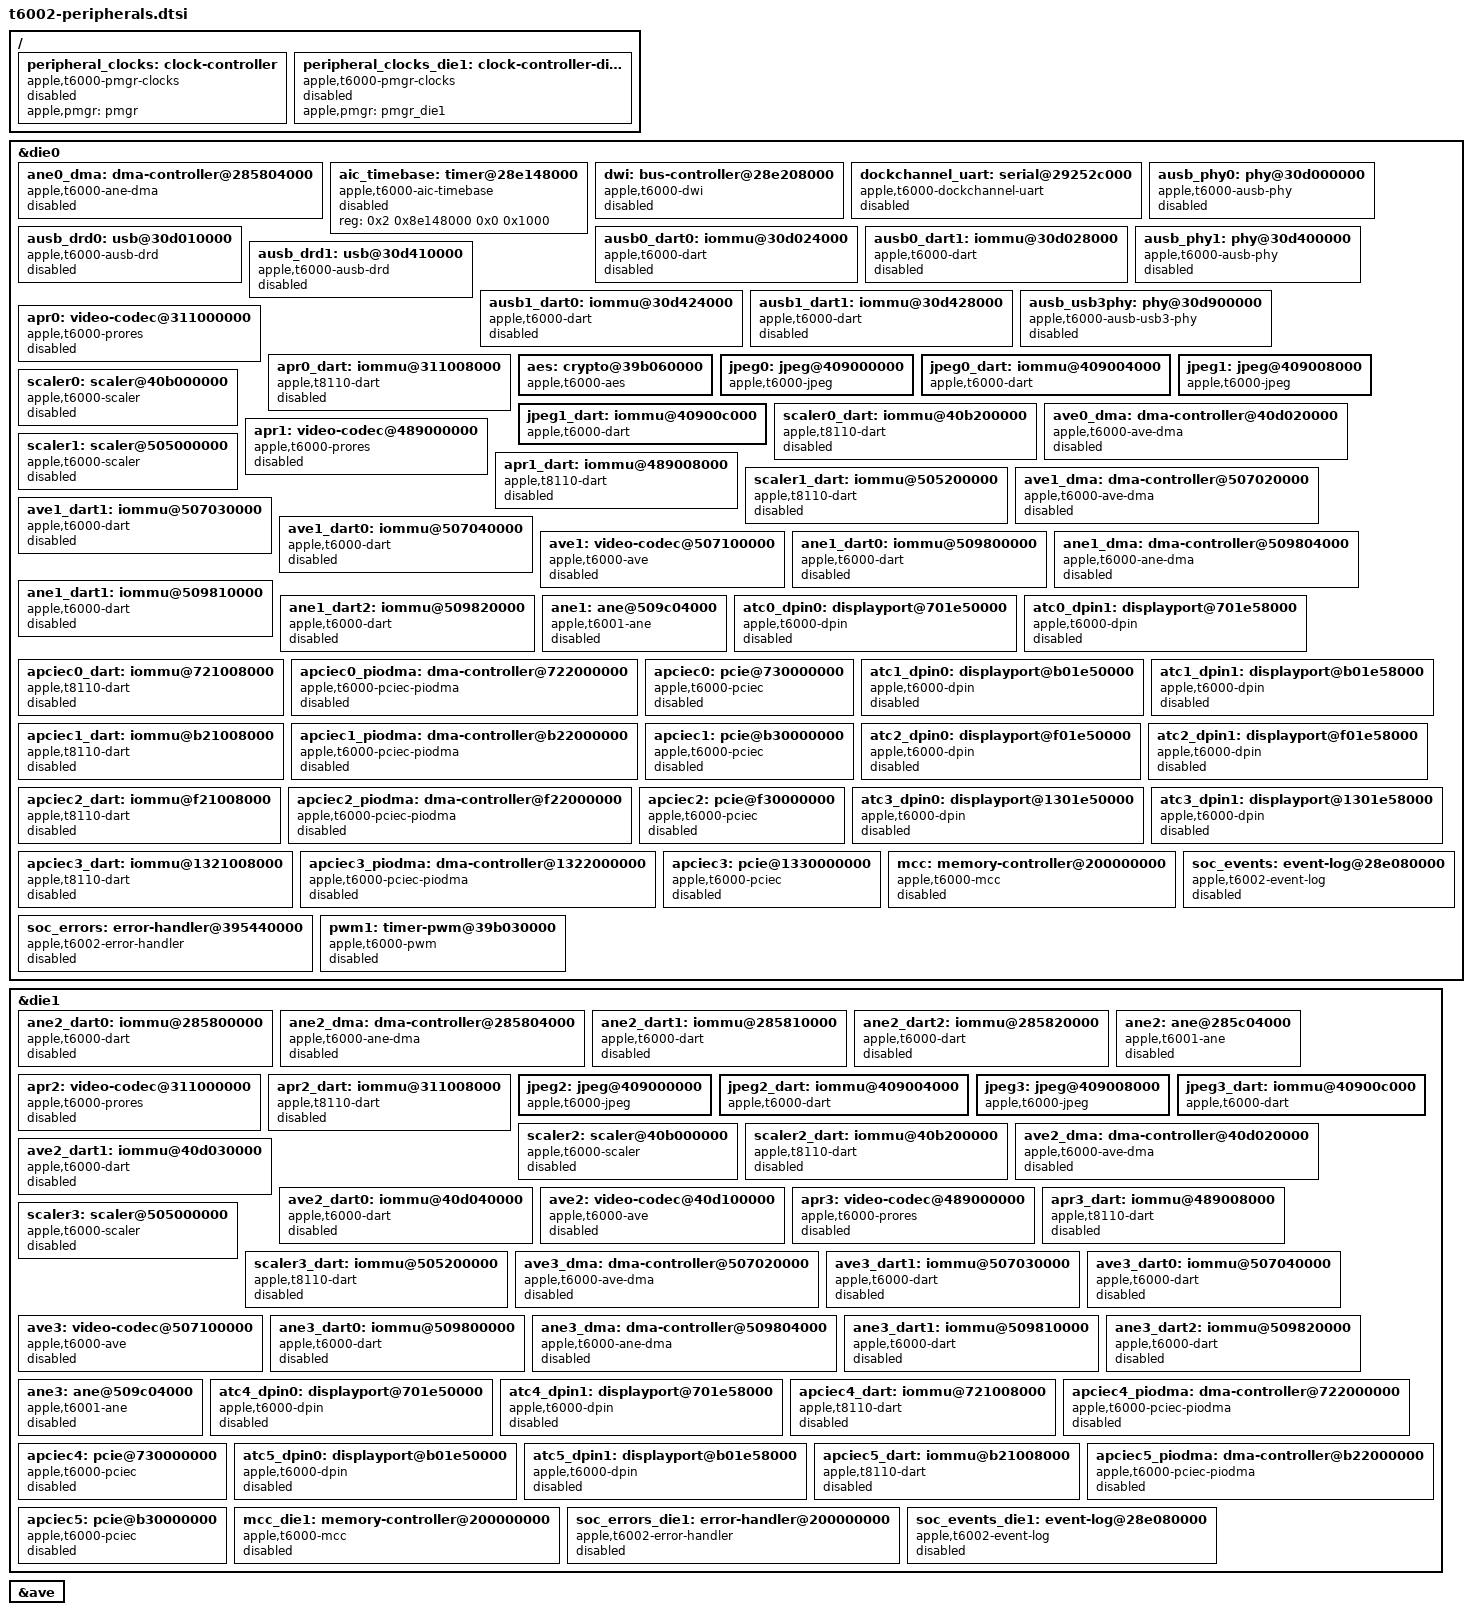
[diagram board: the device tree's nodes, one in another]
// SPDX-License-Identifier: GPL-2.0+ OR MIT
/* Disabled resource descriptions for T6002. */

&die0 {
	ane0_dma: dma-controller@285804000 {
		compatible = "apple,t6000-ane-dma", "apple,ane-dma";
		reg = <0x2 0x85804000 0x0 0x4000>;
		interrupt-parent = <&aic>;
		interrupts = <AIC_IRQ 0 771 IRQ_TYPE_LEVEL_HIGH>;
		power-domains = <&ps_ane_sys>;
		status = "disabled";
	};

	aic_timebase: timer@28e148000 {
		compatible = "apple,t6000-aic-timebase", "apple,aic-timebase";
		reg = <0x2 0x8e148000 0x0 0x1000>;
		status = "disabled";
	};

	dwi: bus-controller@28e208000 {
		compatible = "apple,t6000-dwi", "apple,dwi";
		reg = <0x2 0x8e208000 0x0 0x4000>;
		interrupt-parent = <&aic>;
		interrupts = <AIC_IRQ 0 22 IRQ_TYPE_LEVEL_HIGH>;
		power-domains = <&ps_dwi>;
		status = "disabled";
	};

	/* The DebugUSB DockChannel serial channel; RX is drained in software. */
	dockchannel_uart: serial@29252c000 {
		compatible = "apple,t6000-dockchannel-uart", "apple,dockchannel-uart";
		reg = <0x2 0x9252c000 0x0 0x4000>,
		      <0x2 0x92528000 0x0 0x4000>,
		      <0x2 0x9250c000 0x0 0x18>;
		reg-names = "data", "config", "irq";
		interrupt-parent = <&aic>;
		interrupts = <AIC_IRQ 0 620 IRQ_TYPE_LEVEL_HIGH>;
		apple,sw-drain;
		status = "disabled";
	};

	ausb_phy0: phy@30d000000 {
		compatible = "apple,t6000-ausb-phy", "apple,ausb-phy";
		reg = <0x3 0x0d000000 0x0 0x4000>;
		power-domains = <&ps_c0_usbctl>;
		#phy-cells = <0>;
		phys = <&ausb_usb3phy>;
		status = "disabled";
	};

	ausb_drd0: usb@30d010000 {
		compatible = "apple,t6000-ausb-drd", "apple,ausb-drd";
		reg = <0x3 0x0d010000 0x0 0x11800>,
		      <0x3 0x0d020000 0x0 0x4000>,
		      <0x3 0x0d01c100 0x0 0x4000>,
		      <0x3 0x0d000000 0x0 0x2c000>;
		interrupt-parent = <&aic>;
		interrupts = <AIC_IRQ 0 1155 IRQ_TYPE_LEVEL_HIGH>,
			     <AIC_IRQ 0 1156 IRQ_TYPE_LEVEL_HIGH>,
			     <AIC_IRQ 0 1157 IRQ_TYPE_LEVEL_HIGH>,
			     <AIC_IRQ 0 1158 IRQ_TYPE_LEVEL_HIGH>;
		power-domains = <&ps_c0_usb31drd>;
		iommus = <&ausb0_dart0 3>, <&ausb0_dart1 3>;
		phys = <&ausb_phy0>;
		status = "disabled";
	};

	ausb0_dart0: iommu@30d024000 {
		compatible = "apple,t6000-dart", "apple,t8110-dart";
		reg = <0x3 0x0d024000 0x0 0x4000>;
		interrupt-parent = <&aic>;
		interrupts = <AIC_IRQ 0 1154 IRQ_TYPE_LEVEL_HIGH>;
		#iommu-cells = <1>;
		status = "disabled";
	};

	ausb0_dart1: iommu@30d028000 {
		compatible = "apple,t6000-dart", "apple,t8110-dart";
		reg = <0x3 0x0d028000 0x0 0x4000>;
		interrupt-parent = <&aic>;
		interrupts = <AIC_IRQ 0 1154 IRQ_TYPE_LEVEL_HIGH>;
		#iommu-cells = <1>;
		status = "disabled";
	};

	ausb_phy1: phy@30d400000 {
		compatible = "apple,t6000-ausb-phy", "apple,ausb-phy";
		reg = <0x3 0x0d400000 0x0 0x4000>;
		power-domains = <&ps_c1_usbctl>;
		#phy-cells = <0>;
		phys = <&ausb_usb3phy>;
		status = "disabled";
	};

	ausb_drd1: usb@30d410000 {
		compatible = "apple,t6000-ausb-drd", "apple,ausb-drd";
		reg = <0x3 0x0d410000 0x0 0x11800>,
		      <0x3 0x0d420000 0x0 0x4000>,
		      <0x3 0x0d41c100 0x0 0x4000>,
		      <0x3 0x0d400000 0x0 0x2c000>;
		interrupt-parent = <&aic>;
		interrupts = <AIC_IRQ 0 1163 IRQ_TYPE_LEVEL_HIGH>,
			     <AIC_IRQ 0 1164 IRQ_TYPE_LEVEL_HIGH>,
			     <AIC_IRQ 0 1165 IRQ_TYPE_LEVEL_HIGH>,
			     <AIC_IRQ 0 1166 IRQ_TYPE_LEVEL_HIGH>;
		power-domains = <&ps_c1_usb31drd>;
		iommus = <&ausb1_dart0 3>, <&ausb1_dart1 3>;
		phys = <&ausb_phy1>;
		status = "disabled";
	};

	ausb1_dart0: iommu@30d424000 {
		compatible = "apple,t6000-dart", "apple,t8110-dart";
		reg = <0x3 0x0d424000 0x0 0x4000>;
		interrupt-parent = <&aic>;
		interrupts = <AIC_IRQ 0 1162 IRQ_TYPE_LEVEL_HIGH>;
		#iommu-cells = <1>;
		status = "disabled";
	};

	ausb1_dart1: iommu@30d428000 {
		compatible = "apple,t6000-dart", "apple,t8110-dart";
		reg = <0x3 0x0d428000 0x0 0x4000>;
		interrupt-parent = <&aic>;
		interrupts = <AIC_IRQ 0 1162 IRQ_TYPE_LEVEL_HIGH>;
		#iommu-cells = <1>;
		status = "disabled";
	};

	ausb_usb3phy: phy@30d900000 {
		compatible = "apple,t6000-ausb-usb3-phy", "apple,ausb-usb3-phy";
		reg = <0x3 0x0d900000 0x0 0x4000>,
		      <0x3 0x0d980000 0x0 0x4000>,
		      <0x3 0x0d982000 0x0 0x4000>,
		      <0x3 0x0d982200 0x0 0x4000>,
		      <0x3 0x0d982800 0x0 0x4000>,
		      <0x3 0x0d982a00 0x0 0x4000>,
		      <0x3 0x0d980a00 0x0 0x4000>,
		      <0x3 0x0d980800 0x0 0x4000>,
		      <0x3 0x0d98d000 0x0 0x4000>,
		      <0x3 0x0d994000 0x0 0x4000>,
		      <0x3 0x0d98c000 0x0 0x4000>,
		      <0x3 0x0d993000 0x0 0x4000>,
		      <0x3 0x0d98b000 0x0 0x4000>,
		      <0x3 0x0d992000 0x0 0x4000>,
		      <0x3 0x0d989000 0x0 0x4000>,
		      <0x3 0x0d990000 0x0 0x4000>,
		      <0x3 0x0d981000 0x0 0x4000>,
		      <0x2 0x922bc000 0x0 0x2000>,
		      <0x3 0x0c000000 0x0 0x1000000>,
		      <0x3 0x0d98a000 0x0 0x4000>,
		      <0x3 0x0d991000 0x0 0x4000>;
		power-domains = <&ps_gp_usb_aon>, <&ps_usb>;
		#phy-cells = <0>;
		status = "disabled";
	};

	apr0: video-codec@311000000 {
		compatible = "apple,t6000-prores", "apple,prores";
		reg = <0x3 0x11000000 0x0 0x4000>,
		      <0x3 0x10000000 0x0 0x1000000>;
		interrupt-parent = <&aic>;
		interrupts = <AIC_IRQ 0 1482 IRQ_TYPE_LEVEL_HIGH>;
		power-domains = <&ps_scodec>;
		iommus = <&apr0_dart 0>;
		reg-names = "core", "wrapper";
		status = "disabled";
	};

	apr0_dart: iommu@311008000 {
		compatible = "apple,t8110-dart";
		reg = <0x3 0x11008000 0x0 0x4000>;
		interrupt-parent = <&aic>;
		interrupts = <AIC_IRQ 0 1479 IRQ_TYPE_LEVEL_HIGH>;
		power-domains = <&ps_scodec>;
		#iommu-cells = <1>;
		status = "disabled";
	};

	aes: crypto@39b060000 {
		compatible = "apple,t6000-aes", "apple,aes";
		reg = <0x3 0x9b060000 0x0 0x4000>,
		      <0x2 0x922d0000 0x0 0x8000>;
		interrupt-parent = <&aic>;
		interrupts = <AIC_IRQ 0 1117 IRQ_TYPE_LEVEL_HIGH>;
		power-domains = <&ps_aes>;
		iommus = <&sio_dart_0 1>, <&sio_dart_1 1>;
	};

	jpeg0: jpeg@409000000 {
		compatible = "apple,t6000-jpeg", "apple,jpeg";
		reg = <0x4 0x09000000 0x0 0x4000>;
		interrupt-parent = <&aic>;
		interrupts = <AIC_IRQ 0 1076 IRQ_TYPE_LEVEL_HIGH>;
		power-domains = <&ps_jpg>;
		clocks = <&peripheral_clocks 354>, <&peripheral_clocks 355>;
		iommus = <&jpeg0_dart 0>;
		status = "okay";
	};

	jpeg0_dart: iommu@409004000 {
		compatible = "apple,t6000-dart", "apple,t8110-dart";
		reg = <0x4 0x09004000 0x0 0x4000>;
		interrupt-parent = <&aic>;
		interrupts = <AIC_IRQ 0 1077 IRQ_TYPE_LEVEL_HIGH>;
		power-domains = <&ps_jpg>;
		#iommu-cells = <1>;
		status = "okay";
	};

	jpeg1: jpeg@409008000 {
		compatible = "apple,t6000-jpeg", "apple,jpeg";
		reg = <0x4 0x09008000 0x0 0x4000>;
		interrupt-parent = <&aic>;
		interrupts = <AIC_IRQ 0 1081 IRQ_TYPE_LEVEL_HIGH>;
		power-domains = <&ps_jpg>;
		clocks = <&peripheral_clocks 354>, <&peripheral_clocks 355>;
		iommus = <&jpeg1_dart 0>;
		status = "okay";
	};

	jpeg1_dart: iommu@40900c000 {
		compatible = "apple,t6000-dart", "apple,t8110-dart";
		reg = <0x4 0x0900c000 0x0 0x4000>;
		interrupt-parent = <&aic>;
		interrupts = <AIC_IRQ 0 1082 IRQ_TYPE_LEVEL_HIGH>;
		power-domains = <&ps_jpg>;
		#iommu-cells = <1>;
		status = "okay";
	};

	scaler0: scaler@40b000000 {
		compatible = "apple,t6000-scaler", "apple,scaler";
		reg = <0x4 0x0b000000 0x0 0x28000>,
		      <0x4 0x0b210000 0x0 0x4000>,
		      <0x4 0x0b204000 0x0 0x4000>;
		interrupt-parent = <&aic>;
		interrupts = <AIC_IRQ 0 1085 IRQ_TYPE_LEVEL_HIGH>,
			     <AIC_IRQ 0 1087 IRQ_TYPE_LEVEL_HIGH>;
		power-domains = <&ps_msr0>, <&ps_msr0_ase_core>;
		clocks = <&peripheral_clocks 356>;
		iommus = <&scaler0_dart 0>, <&scaler0_dart 1>;
		resets = <&ps_msr0>;
		status = "disabled";
	};

	scaler0_dart: iommu@40b200000 {
		compatible = "apple,t8110-dart";
		reg = <0x4 0x0b200000 0x0 0x4000>;
		interrupt-parent = <&aic>;
		interrupts = <AIC_IRQ 0 1086 IRQ_TYPE_LEVEL_HIGH>;
		power-domains = <&ps_msr0>;
		#iommu-cells = <1>;
		status = "disabled";
	};

	ave0_dma: dma-controller@40d020000 {
		compatible = "apple,t6000-ave-dma", "apple,ave-dma";
		reg = <0x4 0x0d020000 0x0 0x4000>,
		      <0x4 0x0d044000 0x0 0x4000>;
		interrupt-parent = <&aic>;
		interrupts = <AIC_IRQ 0 1028 IRQ_TYPE_LEVEL_HIGH>;
		power-domains = <&ps_venc_sys>;
		status = "disabled";
	};

	apr1: video-codec@489000000 {
		compatible = "apple,t6000-prores", "apple,prores";
		reg = <0x4 0x89000000 0x0 0x4000>,
		      <0x4 0x88000000 0x0 0x1000000>;
		interrupt-parent = <&aic>;
		interrupts = <AIC_IRQ 0 1514 IRQ_TYPE_LEVEL_HIGH>;
		power-domains = <&ps_prores>;
		iommus = <&apr1_dart 0>;
		reg-names = "core", "wrapper";
		status = "disabled";
	};

	apr1_dart: iommu@489008000 {
		compatible = "apple,t8110-dart";
		reg = <0x4 0x89008000 0x0 0x4000>;
		interrupt-parent = <&aic>;
		interrupts = <AIC_IRQ 0 1511 IRQ_TYPE_LEVEL_HIGH>;
		power-domains = <&ps_prores>;
		#iommu-cells = <1>;
		status = "disabled";
	};

	scaler1: scaler@505000000 {
		compatible = "apple,t6000-scaler", "apple,scaler";
		reg = <0x5 0x05000000 0x0 0x28000>,
		      <0x5 0x05210000 0x0 0x4000>,
		      <0x5 0x05204000 0x0 0x4000>;
		interrupt-parent = <&aic>;
		interrupts = <AIC_IRQ 0 1091 IRQ_TYPE_LEVEL_HIGH>,
			     <AIC_IRQ 0 1093 IRQ_TYPE_LEVEL_HIGH>;
		power-domains = <&ps_msr1>, <&ps_msr1_ase_core>;
		clocks = <&peripheral_clocks 356>;
		iommus = <&scaler1_dart 0>, <&scaler1_dart 1>;
		resets = <&ps_msr1>;
		status = "disabled";
	};

	scaler1_dart: iommu@505200000 {
		compatible = "apple,t8110-dart";
		reg = <0x5 0x05200000 0x0 0x4000>;
		interrupt-parent = <&aic>;
		interrupts = <AIC_IRQ 0 1092 IRQ_TYPE_LEVEL_HIGH>;
		power-domains = <&ps_msr1>;
		#iommu-cells = <1>;
		status = "disabled";
	};

	ave1_dma: dma-controller@507020000 {
		compatible = "apple,t6000-ave-dma", "apple,ave-dma";
		reg = <0x5 0x07020000 0x0 0x4000>,
		      <0x5 0x07044000 0x0 0x4000>;
		interrupt-parent = <&aic>;
		interrupts = <AIC_IRQ 0 1038 IRQ_TYPE_LEVEL_HIGH>;
		power-domains = <&ps_venc1_sys>;
		status = "disabled";
	};

	ave1_dart1: iommu@507030000 {
		compatible = "apple,t6000-dart", "apple,t8110-dart";
		reg = <0x5 0x07030000 0x0 0x4000>;
		interrupt-parent = <&aic>;
		interrupts = <AIC_IRQ 0 1038 IRQ_TYPE_LEVEL_HIGH>;
		power-domains = <&ps_venc1_sys>;
		#iommu-cells = <1>;
		status = "disabled";
	};

	ave1_dart0: iommu@507040000 {
		compatible = "apple,t6000-dart", "apple,t8110-dart";
		reg = <0x5 0x07040000 0x0 0x4000>;
		interrupt-parent = <&aic>;
		interrupts = <AIC_IRQ 0 1038 IRQ_TYPE_LEVEL_HIGH>;
		power-domains = <&ps_venc1_sys>;
		#iommu-cells = <1>;
		status = "disabled";
	};

	ave1: video-codec@507100000 {
		compatible = "apple,t6000-ave";
		reg = <0x5 0x07100000 0x0 0x45c000>,
		      <0x5 0x07050000 0x0 0x8000>,
		      <0x5 0x07800000 0x0 0x800000>,
		      <0x2 0x8e680260 0x0 0x7dc4>,
		      <0x5 0x06000000 0x0 0x1000000>;
		interrupt-parent = <&aic>;
		interrupts = <AIC_IRQ 0 1041 IRQ_TYPE_LEVEL_HIGH>,
			     <AIC_IRQ 0 1035 IRQ_TYPE_LEVEL_HIGH>,
			     <AIC_IRQ 0 1034 IRQ_TYPE_LEVEL_HIGH>,
			     <AIC_IRQ 0 1037 IRQ_TYPE_LEVEL_HIGH>,
			     <AIC_IRQ 0 1036 IRQ_TYPE_LEVEL_HIGH>;
		power-domains = <&ps_venc1_dma>, <&ps_venc1_pipe4>, <&ps_venc1_pipe5>, <&ps_venc1_me0>, <&ps_venc1_me1>;
		clocks = <&peripheral_clocks 454>;
		iommus = <&ave1_dart0 0>, <&ave1_dart1 0>;
		reg-names = "codec", "mailbox", "coproc", "pmgr", "pio";
		power-domain-names = "dma", "pipe4", "pipe5", "me0", "me1";
		status = "disabled";
	};

	ane1_dart0: iommu@509800000 {
		compatible = "apple,t6000-dart", "apple,t8110-dart";
		reg = <0x5 0x09800000 0x0 0x4000>;
		interrupt-parent = <&aic>;
		interrupts = <AIC_IRQ 0 798 IRQ_TYPE_LEVEL_HIGH>;
		power-domains = <&ps_ane1_sys>;
		#iommu-cells = <1>;
		status = "disabled";
	};

	ane1_dma: dma-controller@509804000 {
		compatible = "apple,t6000-ane-dma", "apple,ane-dma";
		reg = <0x5 0x09804000 0x0 0x4000>;
		interrupt-parent = <&aic>;
		interrupts = <AIC_IRQ 0 798 IRQ_TYPE_LEVEL_HIGH>;
		power-domains = <&ps_ane1_sys>;
		status = "disabled";
	};

	ane1_dart1: iommu@509810000 {
		compatible = "apple,t6000-dart", "apple,t8110-dart";
		reg = <0x5 0x09810000 0x0 0x4000>;
		interrupt-parent = <&aic>;
		interrupts = <AIC_IRQ 0 798 IRQ_TYPE_LEVEL_HIGH>;
		power-domains = <&ps_ane1_sys>;
		#iommu-cells = <1>;
		status = "disabled";
	};

	ane1_dart2: iommu@509820000 {
		compatible = "apple,t6000-dart", "apple,t8110-dart";
		reg = <0x5 0x09820000 0x0 0x4000>;
		interrupt-parent = <&aic>;
		interrupts = <AIC_IRQ 0 798 IRQ_TYPE_LEVEL_HIGH>;
		power-domains = <&ps_ane1_sys>;
		#iommu-cells = <1>;
		status = "disabled";
	};

	ane1: ane@509c04000 {
		compatible = "apple,t6001-ane", "apple,ane";
		reg = <0x5 0x09c04000 0x0 0x24000>;
		interrupt-parent = <&aic>;
		interrupts = <AIC_IRQ 0 797 IRQ_TYPE_LEVEL_HIGH>;
		power-domains = <&ps_ane1_sys_cpu>;
		clocks = <&peripheral_clocks 318>, <&peripheral_clocks 319>, <&peripheral_clocks 320>, <&peripheral_clocks 321>;
		iommus = <&ane1_dart0 0>, <&ane1_dart1 0>, <&ane1_dart2 0>;
		reg-names = "engine";
		interrupt-names = "ane";
		status = "disabled";
	};

	atc0_dpin0: displayport@701e50000 {
		compatible = "apple,t6000-dpin", "apple,dpin";
		reg = <0x7 0x01e50000 0x0 0x4000>;
		interrupt-parent = <&aic>;
		interrupts = <AIC_IRQ 0 1306 IRQ_TYPE_LEVEL_HIGH>;
		status = "disabled";
	};

	atc0_dpin1: displayport@701e58000 {
		compatible = "apple,t6000-dpin", "apple,dpin";
		reg = <0x7 0x01e58000 0x0 0x4000>;
		interrupt-parent = <&aic>;
		interrupts = <AIC_IRQ 0 1307 IRQ_TYPE_LEVEL_HIGH>;
		status = "disabled";
	};

	apciec0_dart: iommu@721008000 {
		compatible = "apple,t8110-dart";
		reg = <0x7 0x21008000 0x0 0x4000>;
		interrupt-parent = <&aic>;
		interrupts = <AIC_IRQ 0 1198 IRQ_TYPE_LEVEL_HIGH>;
		#iommu-cells = <1>;
		status = "disabled";
	};

	apciec0_piodma: dma-controller@722000000 {
		compatible = "apple,t6000-pciec-piodma", "apple,pciec-piodma";
		reg = <0x7 0x22000000 0x0 0x4000>,
		      <0x7 0x22004000 0x0 0x4000>,
		      <0x7 0x22008000 0x0 0x4000>,
		      <0x7 0x20008000 0x0 0x4000>;
		interrupt-parent = <&aic>;
		interrupts = <AIC_IRQ 0 1199 IRQ_TYPE_LEVEL_HIGH>;
		iommus = <&apciec0_dart 15>;
		status = "disabled";
	};

	apciec0: pcie@730000000 {
		compatible = "apple,t6000-pciec";
		reg = <0x7 0x30000000 0x0 0x10000000>,
		      <0x7 0x20000000 0x0 0x4000>,
		      <0x7 0x21000000 0x0 0x8000>,
		      <0x7 0x20004000 0x0 0x4000>,
		      <0x7 0x20200000 0x0 0x4000>,
		      <0x7 0x21010000 0x0 0x4000>,
		      <0x7 0x2100c000 0x0 0x4000>;
		interrupt-parent = <&aic>;
		interrupts = <AIC_IRQ 0 1197 IRQ_TYPE_LEVEL_HIGH>;
		power-domains = <&ps_atc0_pcie>;
		device_type = "pci";
		reg-names = "config", "rc", "port0", "fabric", "debug", "ltssm", "intr2axi";
		msi-controller;
		msi-parent = <&apciec0>;
		msi-ranges = <&aic AIC_IRQ 0 1614 IRQ_TYPE_EDGE_RISING 32>;
		iommu-map = <0 &apciec0_dart 0 0x40>;
		iommu-map-mask = <0x3f>;
		bus-range = <0 0x7f>;
		#address-cells = <3>;
		#size-cells = <2>;
		ranges = <0x43000000 0x8 0x0 0x8 0x0 0x2 0x0>,
		         <0x2000000 0x0 0x100000 0xa 0x100000 0x0 0x3ff00000>,
		         <0x42000000 0x0 0x40000000 0xa 0x40000000 0x0 0x40000000>;
		status = "disabled";
	};

	atc1_dpin0: displayport@b01e50000 {
		compatible = "apple,t6000-dpin", "apple,dpin";
		reg = <0xb 0x01e50000 0x0 0x4000>;
		interrupt-parent = <&aic>;
		interrupts = <AIC_IRQ 0 1354 IRQ_TYPE_LEVEL_HIGH>;
		status = "disabled";
	};

	atc1_dpin1: displayport@b01e58000 {
		compatible = "apple,t6000-dpin", "apple,dpin";
		reg = <0xb 0x01e58000 0x0 0x4000>;
		interrupt-parent = <&aic>;
		interrupts = <AIC_IRQ 0 1355 IRQ_TYPE_LEVEL_HIGH>;
		status = "disabled";
	};

	apciec1_dart: iommu@b21008000 {
		compatible = "apple,t8110-dart";
		reg = <0xb 0x21008000 0x0 0x4000>;
		interrupt-parent = <&aic>;
		interrupts = <AIC_IRQ 0 1215 IRQ_TYPE_LEVEL_HIGH>;
		#iommu-cells = <1>;
		status = "disabled";
	};

	apciec1_piodma: dma-controller@b22000000 {
		compatible = "apple,t6000-pciec-piodma", "apple,pciec-piodma";
		reg = <0xb 0x22000000 0x0 0x4000>,
		      <0xb 0x22004000 0x0 0x4000>,
		      <0xb 0x22008000 0x0 0x4000>,
		      <0xb 0x20008000 0x0 0x4000>;
		interrupt-parent = <&aic>;
		interrupts = <AIC_IRQ 0 1216 IRQ_TYPE_LEVEL_HIGH>;
		iommus = <&apciec1_dart 15>;
		status = "disabled";
	};

	apciec1: pcie@b30000000 {
		compatible = "apple,t6000-pciec";
		reg = <0xb 0x30000000 0x0 0x10000000>,
		      <0xb 0x20000000 0x0 0x4000>,
		      <0xb 0x21000000 0x0 0x8000>,
		      <0xb 0x20004000 0x0 0x4000>,
		      <0xb 0x20200000 0x0 0x4000>,
		      <0xb 0x21010000 0x0 0x4000>,
		      <0xb 0x2100c000 0x0 0x4000>;
		interrupt-parent = <&aic>;
		interrupts = <AIC_IRQ 0 1214 IRQ_TYPE_LEVEL_HIGH>;
		power-domains = <&ps_atc1_pcie>;
		device_type = "pci";
		reg-names = "config", "rc", "port0", "fabric", "debug", "ltssm", "intr2axi";
		msi-controller;
		msi-parent = <&apciec1>;
		msi-ranges = <&aic AIC_IRQ 0 1646 IRQ_TYPE_EDGE_RISING 32>;
		iommu-map = <0 &apciec1_dart 0 0x40>;
		iommu-map-mask = <0x3f>;
		bus-range = <0 0x7f>;
		#address-cells = <3>;
		#size-cells = <2>;
		ranges = <0x43000000 0xc 0x0 0xc 0x0 0x2 0x0>,
		         <0x2000000 0x0 0x100000 0xe 0x100000 0x0 0x3ff00000>,
		         <0x42000000 0x0 0x40000000 0xe 0x40000000 0x0 0x40000000>;
		status = "disabled";
	};

	atc2_dpin0: displayport@f01e50000 {
		compatible = "apple,t6000-dpin", "apple,dpin";
		reg = <0xf 0x01e50000 0x0 0x4000>;
		interrupt-parent = <&aic>;
		interrupts = <AIC_IRQ 0 1402 IRQ_TYPE_LEVEL_HIGH>;
		status = "disabled";
	};

	atc2_dpin1: displayport@f01e58000 {
		compatible = "apple,t6000-dpin", "apple,dpin";
		reg = <0xf 0x01e58000 0x0 0x4000>;
		interrupt-parent = <&aic>;
		interrupts = <AIC_IRQ 0 1403 IRQ_TYPE_LEVEL_HIGH>;
		status = "disabled";
	};

	apciec2_dart: iommu@f21008000 {
		compatible = "apple,t8110-dart";
		reg = <0xf 0x21008000 0x0 0x4000>;
		interrupt-parent = <&aic>;
		interrupts = <AIC_IRQ 0 1232 IRQ_TYPE_LEVEL_HIGH>;
		#iommu-cells = <1>;
		status = "disabled";
	};

	apciec2_piodma: dma-controller@f22000000 {
		compatible = "apple,t6000-pciec-piodma", "apple,pciec-piodma";
		reg = <0xf 0x22000000 0x0 0x4000>,
		      <0xf 0x22004000 0x0 0x4000>,
		      <0xf 0x22008000 0x0 0x4000>,
		      <0xf 0x20008000 0x0 0x4000>;
		interrupt-parent = <&aic>;
		interrupts = <AIC_IRQ 0 1233 IRQ_TYPE_LEVEL_HIGH>;
		iommus = <&apciec2_dart 15>;
		status = "disabled";
	};

	apciec2: pcie@f30000000 {
		compatible = "apple,t6000-pciec";
		reg = <0xf 0x30000000 0x0 0x10000000>,
		      <0xf 0x20000000 0x0 0x4000>,
		      <0xf 0x21000000 0x0 0x8000>,
		      <0xf 0x20004000 0x0 0x4000>,
		      <0xf 0x20200000 0x0 0x4000>,
		      <0xf 0x21010000 0x0 0x4000>,
		      <0xf 0x2100c000 0x0 0x4000>;
		interrupt-parent = <&aic>;
		interrupts = <AIC_IRQ 0 1231 IRQ_TYPE_LEVEL_HIGH>;
		power-domains = <&ps_atc2_pcie>;
		device_type = "pci";
		reg-names = "config", "rc", "port0", "fabric", "debug", "ltssm", "intr2axi";
		msi-controller;
		msi-parent = <&apciec2>;
		msi-ranges = <&aic AIC_IRQ 0 1678 IRQ_TYPE_EDGE_RISING 32>;
		iommu-map = <0 &apciec2_dart 0 0x40>;
		iommu-map-mask = <0x3f>;
		bus-range = <0 0x7f>;
		#address-cells = <3>;
		#size-cells = <2>;
		ranges = <0x43000000 0x10 0x0 0x10 0x0 0x2 0x0>,
		         <0x2000000 0x0 0x100000 0x12 0x100000 0x0 0x3ff00000>,
		         <0x42000000 0x0 0x40000000 0x12 0x40000000 0x0 0x40000000>;
		status = "disabled";
	};

	atc3_dpin0: displayport@1301e50000 {
		compatible = "apple,t6000-dpin", "apple,dpin";
		reg = <0x13 0x01e50000 0x0 0x4000>;
		interrupt-parent = <&aic>;
		interrupts = <AIC_IRQ 0 1450 IRQ_TYPE_LEVEL_HIGH>;
		status = "disabled";
	};

	atc3_dpin1: displayport@1301e58000 {
		compatible = "apple,t6000-dpin", "apple,dpin";
		reg = <0x13 0x01e58000 0x0 0x4000>;
		interrupt-parent = <&aic>;
		interrupts = <AIC_IRQ 0 1451 IRQ_TYPE_LEVEL_HIGH>;
		status = "disabled";
	};

	apciec3_dart: iommu@1321008000 {
		compatible = "apple,t8110-dart";
		reg = <0x13 0x21008000 0x0 0x4000>;
		interrupt-parent = <&aic>;
		interrupts = <AIC_IRQ 0 1249 IRQ_TYPE_LEVEL_HIGH>;
		#iommu-cells = <1>;
		status = "disabled";
	};

	apciec3_piodma: dma-controller@1322000000 {
		compatible = "apple,t6000-pciec-piodma", "apple,pciec-piodma";
		reg = <0x13 0x22000000 0x0 0x4000>,
		      <0x13 0x22004000 0x0 0x4000>,
		      <0x13 0x22008000 0x0 0x4000>,
		      <0x13 0x20008000 0x0 0x4000>;
		interrupt-parent = <&aic>;
		interrupts = <AIC_IRQ 0 1250 IRQ_TYPE_LEVEL_HIGH>;
		iommus = <&apciec3_dart 15>;
		status = "disabled";
	};

	apciec3: pcie@1330000000 {
		compatible = "apple,t6000-pciec";
		reg = <0x13 0x30000000 0x0 0x10000000>,
		      <0x13 0x20000000 0x0 0x4000>,
		      <0x13 0x21000000 0x0 0x8000>,
		      <0x13 0x20004000 0x0 0x4000>,
		      <0x13 0x20200000 0x0 0x4000>,
		      <0x13 0x21010000 0x0 0x4000>,
		      <0x13 0x2100c000 0x0 0x4000>;
		interrupt-parent = <&aic>;
		interrupts = <AIC_IRQ 0 1248 IRQ_TYPE_LEVEL_HIGH>;
		power-domains = <&ps_atc3_pcie>;
		device_type = "pci";
		reg-names = "config", "rc", "port0", "fabric", "debug", "ltssm", "intr2axi";
		msi-controller;
		msi-parent = <&apciec3>;
		msi-ranges = <&aic AIC_IRQ 0 1710 IRQ_TYPE_EDGE_RISING 32>;
		iommu-map = <0 &apciec3_dart 0 0x40>;
		iommu-map-mask = <0x3f>;
		bus-range = <0 0x7f>;
		#address-cells = <3>;
		#size-cells = <2>;
		ranges = <0x43000000 0x14 0x0 0x14 0x0 0x2 0x0>,
		         <0x2000000 0x0 0x100000 0x16 0x100000 0x0 0x3ff00000>,
		         <0x42000000 0x0 0x40000000 0x16 0x40000000 0x0 0x40000000>;
		status = "disabled";
	};
};

&die1 {
	ane2_dart0: iommu@285800000 {
		compatible = "apple,t6000-dart", "apple,t8110-dart";
		reg = <0x2 0x85800000 0x0 0x4000>;
		interrupt-parent = <&aic>;
		interrupts = <AIC_IRQ 1 771 IRQ_TYPE_LEVEL_HIGH>;
		power-domains = <&ps_ane_sys_die1>;
		#iommu-cells = <1>;
		status = "disabled";
	};

	ane2_dma: dma-controller@285804000 {
		compatible = "apple,t6000-ane-dma", "apple,ane-dma";
		reg = <0x2 0x85804000 0x0 0x4000>;
		interrupt-parent = <&aic>;
		interrupts = <AIC_IRQ 1 771 IRQ_TYPE_LEVEL_HIGH>;
		power-domains = <&ps_ane_sys_die1>;
		status = "disabled";
	};

	ane2_dart1: iommu@285810000 {
		compatible = "apple,t6000-dart", "apple,t8110-dart";
		reg = <0x2 0x85810000 0x0 0x4000>;
		interrupt-parent = <&aic>;
		interrupts = <AIC_IRQ 1 771 IRQ_TYPE_LEVEL_HIGH>;
		power-domains = <&ps_ane_sys_die1>;
		#iommu-cells = <1>;
		status = "disabled";
	};

	ane2_dart2: iommu@285820000 {
		compatible = "apple,t6000-dart", "apple,t8110-dart";
		reg = <0x2 0x85820000 0x0 0x4000>;
		interrupt-parent = <&aic>;
		interrupts = <AIC_IRQ 1 771 IRQ_TYPE_LEVEL_HIGH>;
		power-domains = <&ps_ane_sys_die1>;
		#iommu-cells = <1>;
		status = "disabled";
	};

	ane2: ane@285c04000 {
		compatible = "apple,t6001-ane", "apple,ane";
		reg = <0x2 0x85c04000 0x0 0x24000>;
		interrupt-parent = <&aic>;
		interrupts = <AIC_IRQ 1 770 IRQ_TYPE_LEVEL_HIGH>;
		power-domains = <&ps_ane_sys_cpu_die1>;
		clocks = <&peripheral_clocks_die1 318>, <&peripheral_clocks_die1 319>, <&peripheral_clocks_die1 320>, <&peripheral_clocks_die1 321>;
		iommus = <&ane2_dart0 0>, <&ane2_dart1 0>, <&ane2_dart2 0>;
		reg-names = "engine";
		interrupt-names = "ane";
		status = "disabled";
	};

	apr2: video-codec@311000000 {
		compatible = "apple,t6000-prores", "apple,prores";
		reg = <0x3 0x11000000 0x0 0x4000>,
		      <0x3 0x10000000 0x0 0x1000000>;
		interrupt-parent = <&aic>;
		interrupts = <AIC_IRQ 1 1482 IRQ_TYPE_LEVEL_HIGH>;
		power-domains = <&ps_scodec_die1>;
		iommus = <&apr2_dart 0>;
		reg-names = "core", "wrapper";
		status = "disabled";
	};

	apr2_dart: iommu@311008000 {
		compatible = "apple,t8110-dart";
		reg = <0x3 0x11008000 0x0 0x4000>;
		interrupt-parent = <&aic>;
		interrupts = <AIC_IRQ 1 1479 IRQ_TYPE_LEVEL_HIGH>;
		power-domains = <&ps_scodec_die1>;
		#iommu-cells = <1>;
		status = "disabled";
	};

	jpeg2: jpeg@409000000 {
		compatible = "apple,t6000-jpeg", "apple,jpeg";
		reg = <0x4 0x09000000 0x0 0x4000>;
		interrupt-parent = <&aic>;
		interrupts = <AIC_IRQ 1 1076 IRQ_TYPE_LEVEL_HIGH>;
		power-domains = <&ps_jpg_die1>;
		clocks = <&peripheral_clocks_die1 354>, <&peripheral_clocks_die1 355>;
		iommus = <&jpeg2_dart 0>;
		status = "okay";
	};

	jpeg2_dart: iommu@409004000 {
		compatible = "apple,t6000-dart", "apple,t8110-dart";
		reg = <0x4 0x09004000 0x0 0x4000>;
		interrupt-parent = <&aic>;
		interrupts = <AIC_IRQ 1 1077 IRQ_TYPE_LEVEL_HIGH>;
		power-domains = <&ps_jpg_die1>;
		#iommu-cells = <1>;
		status = "okay";
	};

	jpeg3: jpeg@409008000 {
		compatible = "apple,t6000-jpeg", "apple,jpeg";
		reg = <0x4 0x09008000 0x0 0x4000>;
		interrupt-parent = <&aic>;
		interrupts = <AIC_IRQ 1 1081 IRQ_TYPE_LEVEL_HIGH>;
		power-domains = <&ps_jpg_die1>;
		clocks = <&peripheral_clocks_die1 354>, <&peripheral_clocks_die1 355>;
		iommus = <&jpeg3_dart 0>;
		status = "okay";
	};

	jpeg3_dart: iommu@40900c000 {
		compatible = "apple,t6000-dart", "apple,t8110-dart";
		reg = <0x4 0x0900c000 0x0 0x4000>;
		interrupt-parent = <&aic>;
		interrupts = <AIC_IRQ 1 1082 IRQ_TYPE_LEVEL_HIGH>;
		power-domains = <&ps_jpg_die1>;
		#iommu-cells = <1>;
		status = "okay";
	};

	scaler2: scaler@40b000000 {
		compatible = "apple,t6000-scaler", "apple,scaler";
		reg = <0x4 0x0b000000 0x0 0x28000>,
		      <0x4 0x0b210000 0x0 0x4000>,
		      <0x4 0x0b204000 0x0 0x4000>;
		interrupt-parent = <&aic>;
		interrupts = <AIC_IRQ 1 1085 IRQ_TYPE_LEVEL_HIGH>,
			     <AIC_IRQ 1 1087 IRQ_TYPE_LEVEL_HIGH>;
		power-domains = <&ps_msr0_die1>, <&ps_msr0_ase_core_die1>;
		clocks = <&peripheral_clocks_die1 356>;
		iommus = <&scaler2_dart 0>, <&scaler2_dart 1>;
		resets = <&ps_msr0_die1>;
		status = "disabled";
	};

	scaler2_dart: iommu@40b200000 {
		compatible = "apple,t8110-dart";
		reg = <0x4 0x0b200000 0x0 0x4000>;
		interrupt-parent = <&aic>;
		interrupts = <AIC_IRQ 1 1086 IRQ_TYPE_LEVEL_HIGH>;
		power-domains = <&ps_msr0_die1>;
		#iommu-cells = <1>;
		status = "disabled";
	};

	ave2_dma: dma-controller@40d020000 {
		compatible = "apple,t6000-ave-dma", "apple,ave-dma";
		reg = <0x4 0x0d020000 0x0 0x4000>,
		      <0x4 0x0d044000 0x0 0x4000>;
		interrupt-parent = <&aic>;
		interrupts = <AIC_IRQ 1 1028 IRQ_TYPE_LEVEL_HIGH>;
		power-domains = <&ps_venc_sys_die1>;
		status = "disabled";
	};

	ave2_dart1: iommu@40d030000 {
		compatible = "apple,t6000-dart", "apple,t8110-dart";
		reg = <0x4 0x0d030000 0x0 0x4000>;
		interrupt-parent = <&aic>;
		interrupts = <AIC_IRQ 1 1028 IRQ_TYPE_LEVEL_HIGH>;
		power-domains = <&ps_venc_sys_die1>;
		#iommu-cells = <1>;
		status = "disabled";
	};

	ave2_dart0: iommu@40d040000 {
		compatible = "apple,t6000-dart", "apple,t8110-dart";
		reg = <0x4 0x0d040000 0x0 0x4000>;
		interrupt-parent = <&aic>;
		interrupts = <AIC_IRQ 1 1028 IRQ_TYPE_LEVEL_HIGH>;
		power-domains = <&ps_venc_sys_die1>;
		#iommu-cells = <1>;
		status = "disabled";
	};

	ave2: video-codec@40d100000 {
		compatible = "apple,t6000-ave";
		reg = <0x4 0x0d100000 0x0 0x45c000>,
		      <0x4 0x0d050000 0x0 0x8000>,
		      <0x4 0x0d800000 0x0 0x800000>,
		      <0x2 0x8e588000 0x0 0x24>,
		      <0x4 0x0c000000 0x0 0x1000000>;
		interrupt-parent = <&aic>;
		interrupts = <AIC_IRQ 1 1031 IRQ_TYPE_LEVEL_HIGH>,
			     <AIC_IRQ 1 1025 IRQ_TYPE_LEVEL_HIGH>,
			     <AIC_IRQ 1 1024 IRQ_TYPE_LEVEL_HIGH>,
			     <AIC_IRQ 1 1027 IRQ_TYPE_LEVEL_HIGH>,
			     <AIC_IRQ 1 1026 IRQ_TYPE_LEVEL_HIGH>;
		power-domains = <&ps_venc_dma_die1>, <&ps_venc_pipe4_die1>, <&ps_venc_pipe5_die1>, <&ps_venc_me0_die1>, <&ps_venc_me1_die1>;
		clocks = <&peripheral_clocks_die1 350>;
		iommus = <&ave2_dart0 0>, <&ave2_dart1 0>;
		reg-names = "codec", "mailbox", "coproc", "pmgr", "pio";
		power-domain-names = "dma", "pipe4", "pipe5", "me0", "me1";
		status = "disabled";
	};

	apr3: video-codec@489000000 {
		compatible = "apple,t6000-prores", "apple,prores";
		reg = <0x4 0x89000000 0x0 0x4000>,
		      <0x4 0x88000000 0x0 0x1000000>;
		interrupt-parent = <&aic>;
		interrupts = <AIC_IRQ 1 1514 IRQ_TYPE_LEVEL_HIGH>;
		power-domains = <&ps_prores_die1>;
		iommus = <&apr3_dart 0>;
		reg-names = "core", "wrapper";
		status = "disabled";
	};

	apr3_dart: iommu@489008000 {
		compatible = "apple,t8110-dart";
		reg = <0x4 0x89008000 0x0 0x4000>;
		interrupt-parent = <&aic>;
		interrupts = <AIC_IRQ 1 1511 IRQ_TYPE_LEVEL_HIGH>;
		power-domains = <&ps_prores_die1>;
		#iommu-cells = <1>;
		status = "disabled";
	};

	scaler3: scaler@505000000 {
		compatible = "apple,t6000-scaler", "apple,scaler";
		reg = <0x5 0x05000000 0x0 0x28000>,
		      <0x5 0x05210000 0x0 0x4000>,
		      <0x5 0x05204000 0x0 0x4000>;
		interrupt-parent = <&aic>;
		interrupts = <AIC_IRQ 1 1091 IRQ_TYPE_LEVEL_HIGH>,
			     <AIC_IRQ 1 1093 IRQ_TYPE_LEVEL_HIGH>;
		power-domains = <&ps_msr1_die1>, <&ps_msr1_ase_core_die1>;
		clocks = <&peripheral_clocks_die1 356>;
		iommus = <&scaler3_dart 0>, <&scaler3_dart 1>;
		resets = <&ps_msr1_die1>;
		status = "disabled";
	};

	scaler3_dart: iommu@505200000 {
		compatible = "apple,t8110-dart";
		reg = <0x5 0x05200000 0x0 0x4000>;
		interrupt-parent = <&aic>;
		interrupts = <AIC_IRQ 1 1092 IRQ_TYPE_LEVEL_HIGH>;
		power-domains = <&ps_msr1_die1>;
		#iommu-cells = <1>;
		status = "disabled";
	};

	ave3_dma: dma-controller@507020000 {
		compatible = "apple,t6000-ave-dma", "apple,ave-dma";
		reg = <0x5 0x07020000 0x0 0x4000>,
		      <0x5 0x07044000 0x0 0x4000>;
		interrupt-parent = <&aic>;
		interrupts = <AIC_IRQ 1 1038 IRQ_TYPE_LEVEL_HIGH>;
		power-domains = <&ps_venc1_sys_die1>;
		status = "disabled";
	};

	ave3_dart1: iommu@507030000 {
		compatible = "apple,t6000-dart", "apple,t8110-dart";
		reg = <0x5 0x07030000 0x0 0x4000>;
		interrupt-parent = <&aic>;
		interrupts = <AIC_IRQ 1 1038 IRQ_TYPE_LEVEL_HIGH>;
		power-domains = <&ps_venc1_sys_die1>;
		#iommu-cells = <1>;
		status = "disabled";
	};

	ave3_dart0: iommu@507040000 {
		compatible = "apple,t6000-dart", "apple,t8110-dart";
		reg = <0x5 0x07040000 0x0 0x4000>;
		interrupt-parent = <&aic>;
		interrupts = <AIC_IRQ 1 1038 IRQ_TYPE_LEVEL_HIGH>;
		power-domains = <&ps_venc1_sys_die1>;
		#iommu-cells = <1>;
		status = "disabled";
	};

	ave3: video-codec@507100000 {
		compatible = "apple,t6000-ave";
		reg = <0x5 0x07100000 0x0 0x45c000>,
		      <0x5 0x07050000 0x0 0x8000>,
		      <0x5 0x07800000 0x0 0x800000>,
		      <0x2 0x8e680260 0x0 0x7dc4>,
		      <0x5 0x06000000 0x0 0x1000000>;
		interrupt-parent = <&aic>;
		interrupts = <AIC_IRQ 1 1041 IRQ_TYPE_LEVEL_HIGH>,
			     <AIC_IRQ 1 1035 IRQ_TYPE_LEVEL_HIGH>,
			     <AIC_IRQ 1 1034 IRQ_TYPE_LEVEL_HIGH>,
			     <AIC_IRQ 1 1037 IRQ_TYPE_LEVEL_HIGH>,
			     <AIC_IRQ 1 1036 IRQ_TYPE_LEVEL_HIGH>;
		power-domains = <&ps_venc1_dma_die1>, <&ps_venc1_pipe4_die1>, <&ps_venc1_pipe5_die1>, <&ps_venc1_me0_die1>, <&ps_venc1_me1_die1>;
		clocks = <&peripheral_clocks_die1 454>;
		iommus = <&ave3_dart0 0>, <&ave3_dart1 0>;
		reg-names = "codec", "mailbox", "coproc", "pmgr", "pio";
		power-domain-names = "dma", "pipe4", "pipe5", "me0", "me1";
		status = "disabled";
	};

	ane3_dart0: iommu@509800000 {
		compatible = "apple,t6000-dart", "apple,t8110-dart";
		reg = <0x5 0x09800000 0x0 0x4000>;
		interrupt-parent = <&aic>;
		interrupts = <AIC_IRQ 1 798 IRQ_TYPE_LEVEL_HIGH>;
		power-domains = <&ps_ane1_sys_die1>;
		#iommu-cells = <1>;
		status = "disabled";
	};

	ane3_dma: dma-controller@509804000 {
		compatible = "apple,t6000-ane-dma", "apple,ane-dma";
		reg = <0x5 0x09804000 0x0 0x4000>;
		interrupt-parent = <&aic>;
		interrupts = <AIC_IRQ 1 798 IRQ_TYPE_LEVEL_HIGH>;
		power-domains = <&ps_ane1_sys_die1>;
		status = "disabled";
	};

	ane3_dart1: iommu@509810000 {
		compatible = "apple,t6000-dart", "apple,t8110-dart";
		reg = <0x5 0x09810000 0x0 0x4000>;
		interrupt-parent = <&aic>;
		interrupts = <AIC_IRQ 1 798 IRQ_TYPE_LEVEL_HIGH>;
		power-domains = <&ps_ane1_sys_die1>;
		#iommu-cells = <1>;
		status = "disabled";
	};

	ane3_dart2: iommu@509820000 {
		compatible = "apple,t6000-dart", "apple,t8110-dart";
		reg = <0x5 0x09820000 0x0 0x4000>;
		interrupt-parent = <&aic>;
		interrupts = <AIC_IRQ 1 798 IRQ_TYPE_LEVEL_HIGH>;
		power-domains = <&ps_ane1_sys_die1>;
		#iommu-cells = <1>;
		status = "disabled";
	};

	ane3: ane@509c04000 {
		compatible = "apple,t6001-ane", "apple,ane";
		reg = <0x5 0x09c04000 0x0 0x24000>;
		interrupt-parent = <&aic>;
		interrupts = <AIC_IRQ 1 797 IRQ_TYPE_LEVEL_HIGH>;
		power-domains = <&ps_ane1_sys_cpu_die1>;
		clocks = <&peripheral_clocks_die1 318>, <&peripheral_clocks_die1 319>, <&peripheral_clocks_die1 320>, <&peripheral_clocks_die1 321>;
		iommus = <&ane3_dart0 0>, <&ane3_dart1 0>, <&ane3_dart2 0>;
		reg-names = "engine";
		interrupt-names = "ane";
		status = "disabled";
	};

	atc4_dpin0: displayport@701e50000 {
		compatible = "apple,t6000-dpin", "apple,dpin";
		reg = <0x7 0x01e50000 0x0 0x4000>;
		interrupt-parent = <&aic>;
		interrupts = <AIC_IRQ 1 1306 IRQ_TYPE_LEVEL_HIGH>;
		status = "disabled";
	};

	atc4_dpin1: displayport@701e58000 {
		compatible = "apple,t6000-dpin", "apple,dpin";
		reg = <0x7 0x01e58000 0x0 0x4000>;
		interrupt-parent = <&aic>;
		interrupts = <AIC_IRQ 1 1307 IRQ_TYPE_LEVEL_HIGH>;
		status = "disabled";
	};

	apciec4_dart: iommu@721008000 {
		compatible = "apple,t8110-dart";
		reg = <0x7 0x21008000 0x0 0x4000>;
		interrupt-parent = <&aic>;
		interrupts = <AIC_IRQ 1 1198 IRQ_TYPE_LEVEL_HIGH>;
		#iommu-cells = <1>;
		status = "disabled";
	};

	apciec4_piodma: dma-controller@722000000 {
		compatible = "apple,t6000-pciec-piodma", "apple,pciec-piodma";
		reg = <0x7 0x22000000 0x0 0x4000>,
		      <0x7 0x22004000 0x0 0x4000>,
		      <0x7 0x22008000 0x0 0x4000>,
		      <0x7 0x20008000 0x0 0x4000>;
		interrupt-parent = <&aic>;
		interrupts = <AIC_IRQ 1 1199 IRQ_TYPE_LEVEL_HIGH>;
		iommus = <&apciec4_dart 15>;
		status = "disabled";
	};

	apciec4: pcie@730000000 {
		compatible = "apple,t6000-pciec";
		reg = <0x7 0x30000000 0x0 0x10000000>,
		      <0x7 0x20000000 0x0 0x4000>,
		      <0x7 0x21000000 0x0 0x8000>,
		      <0x7 0x20004000 0x0 0x4000>,
		      <0x7 0x20200000 0x0 0x4000>,
		      <0x7 0x21010000 0x0 0x4000>,
		      <0x7 0x2100c000 0x0 0x4000>;
		interrupt-parent = <&aic>;
		interrupts = <AIC_IRQ 1 1197 IRQ_TYPE_LEVEL_HIGH>;
		power-domains = <&ps_atc0_pcie_die1>;
		device_type = "pci";
		reg-names = "config", "rc", "port0", "fabric", "debug", "ltssm", "intr2axi";
		msi-controller;
		msi-parent = <&apciec4>;
		msi-ranges = <&aic AIC_IRQ 1 1614 IRQ_TYPE_EDGE_RISING 32>;
		iommu-map = <0 &apciec4_dart 0 0x40>;
		iommu-map-mask = <0x3f>;
		bus-range = <0 0x7f>;
		#address-cells = <3>;
		#size-cells = <2>;
		ranges = <0x43000000 0x28 0x0 0x8 0x0 0x2 0x0>,
		         <0x2000000 0x0 0x100000 0xa 0x100000 0x0 0x3ff00000>,
		         <0x42000000 0x0 0x40000000 0xa 0x40000000 0x0 0x40000000>;
		status = "disabled";
	};

	atc5_dpin0: displayport@b01e50000 {
		compatible = "apple,t6000-dpin", "apple,dpin";
		reg = <0xb 0x01e50000 0x0 0x4000>;
		interrupt-parent = <&aic>;
		interrupts = <AIC_IRQ 1 1354 IRQ_TYPE_LEVEL_HIGH>;
		status = "disabled";
	};

	atc5_dpin1: displayport@b01e58000 {
		compatible = "apple,t6000-dpin", "apple,dpin";
		reg = <0xb 0x01e58000 0x0 0x4000>;
		interrupt-parent = <&aic>;
		interrupts = <AIC_IRQ 1 1355 IRQ_TYPE_LEVEL_HIGH>;
		status = "disabled";
	};

	apciec5_dart: iommu@b21008000 {
		compatible = "apple,t8110-dart";
		reg = <0xb 0x21008000 0x0 0x4000>;
		interrupt-parent = <&aic>;
		interrupts = <AIC_IRQ 1 1215 IRQ_TYPE_LEVEL_HIGH>;
		#iommu-cells = <1>;
		status = "disabled";
	};

	apciec5_piodma: dma-controller@b22000000 {
		compatible = "apple,t6000-pciec-piodma", "apple,pciec-piodma";
		reg = <0xb 0x22000000 0x0 0x4000>,
		      <0xb 0x22004000 0x0 0x4000>,
		      <0xb 0x22008000 0x0 0x4000>,
		      <0xb 0x20008000 0x0 0x4000>;
		interrupt-parent = <&aic>;
		interrupts = <AIC_IRQ 1 1216 IRQ_TYPE_LEVEL_HIGH>;
		iommus = <&apciec5_dart 15>;
		status = "disabled";
	};

	apciec5: pcie@b30000000 {
		compatible = "apple,t6000-pciec";
		reg = <0xb 0x30000000 0x0 0x10000000>,
		      <0xb 0x20000000 0x0 0x4000>,
		      <0xb 0x21000000 0x0 0x8000>,
		      <0xb 0x20004000 0x0 0x4000>,
		      <0xb 0x20200000 0x0 0x4000>,
		      <0xb 0x21010000 0x0 0x4000>,
		      <0xb 0x2100c000 0x0 0x4000>;
		interrupt-parent = <&aic>;
		interrupts = <AIC_IRQ 1 1214 IRQ_TYPE_LEVEL_HIGH>;
		power-domains = <&ps_atc1_pcie_die1>;
		device_type = "pci";
		reg-names = "config", "rc", "port0", "fabric", "debug", "ltssm", "intr2axi";
		msi-controller;
		msi-parent = <&apciec5>;
		msi-ranges = <&aic AIC_IRQ 1 1646 IRQ_TYPE_EDGE_RISING 32>;
		iommu-map = <0 &apciec5_dart 0 0x40>;
		iommu-map-mask = <0x3f>;
		bus-range = <0 0x7f>;
		#address-cells = <3>;
		#size-cells = <2>;
		ranges = <0x43000000 0x2c 0x0 0xc 0x0 0x2 0x0>,
		         <0x2000000 0x0 0x100000 0xe 0x100000 0x0 0x3ff00000>,
		         <0x42000000 0x0 0x40000000 0xe 0x40000000 0x0 0x40000000>;
		status = "disabled";
	};
};

/ {
	peripheral_clocks: clock-controller {
		compatible = "apple,t6000-pmgr-clocks", "apple,pmgr-clocks";
		#clock-cells = <1>;
		apple,pmgr = <&pmgr>;
		status = "disabled";
	};

	peripheral_clocks_die1: clock-controller-die1 {
		compatible = "apple,t6000-pmgr-clocks", "apple,pmgr-clocks";
		#clock-cells = <1>;
		apple,pmgr = <&pmgr_die1>;
		status = "disabled";
	};
};

&die0 {
	mcc: memory-controller@200000000 {
		compatible = "apple,t6000-mcc", "apple,mcc";
		reg = <0x2 0x00000000 0x0 0x1000000>,
		      <0x2 0x01000000 0x0 0x1000000>,
		      <0x2 0x02000000 0x0 0x1000000>,
		      <0x2 0x03000000 0x0 0x1000000>,
		      <0x2 0x04000000 0x0 0x1000000>,
		      <0x2 0x05000000 0x0 0x1000000>,
		      <0x2 0x06000000 0x0 0x1000000>,
		      <0x2 0x07000000 0x0 0x1000000>;
		status = "disabled";
	};

	soc_errors: error-handler@395440000 {
		compatible = "apple,t6002-error-handler", "apple,soc-error-handler";
		reg = <0x3 0x95440000 0x0 0x40000>,
		      <0x2 0x8e000000 0x0 0x80000>,
		      <0x2 0x8e080000 0x0 0x80000>,
		      <0x2 0x00000000 0x0 0x1000000>,
		      <0x2 0x01000000 0x0 0x1000000>,
		      <0x2 0x02000000 0x0 0x1000000>,
		      <0x2 0x03000000 0x0 0x1000000>,
		      <0x2 0x04000000 0x0 0x1000000>,
		      <0x2 0x05000000 0x0 0x1000000>,
		      <0x2 0x06000000 0x0 0x1000000>,
		      <0x2 0x07000000 0x0 0x1000000>,
		      <0x2 0x82000000 0x0 0x4000>,
		      <0x3 0x04000000 0x0 0x4000>,
		      <0x3 0x83000000 0x0 0x4000>,
		      <0x4 0x02000000 0x0 0x4000>,
		      <0x4 0x82000000 0x0 0x4000>,
		      <0x5 0x02000000 0x0 0x4000>,
		      <0x2 0x58d00000 0x0 0x20000>,
		      <0x2 0x59100000 0x0 0x20000>,
		      <0x2 0x5ad00000 0x0 0x20000>,
		      <0x2 0x5b100000 0x0 0x20000>,
		      <0x2 0x60000000 0x0 0x20000>,
		      <0x2 0x60000000 0x0 0x20000>,
		      <0x2 0x59500000 0x0 0x20000>,
		      <0x2 0x5b500000 0x0 0x20000>,
		      <0x2 0x5b900000 0x0 0x20000>,
		      <0x2 0x4fa00000 0x0 0x20000>,
		      <0x2 0x50a00000 0x0 0x20000>,
		      <0x2 0x50e00000 0x0 0x20000>,
		      <0x2 0x4fa80000 0x0 0x20000>,
		      <0x2 0x50a80000 0x0 0x20000>,
		      <0x2 0x64300000 0x0 0x20000>,
		      <0x2 0x65300000 0x0 0x20000>,
		      <0x2 0x64700000 0x0 0x20000>,
		      <0x2 0x66300000 0x0 0x20000>,
		      <0x2 0x65700000 0x0 0x20000>,
		      <0x2 0x67300000 0x0 0x20000>,
		      <0x2 0x6a300000 0x0 0x20000>,
		      <0x2 0x68600000 0x0 0x20000>,
		      <0x2 0x6b300000 0x0 0x20000>,
		      <0x2 0x69600000 0x0 0x20000>,
		      <0x2 0x64b00000 0x0 0x20000>,
		      <0x2 0x66700000 0x0 0x20000>,
		      <0x2 0x65b00000 0x0 0x20000>,
		      <0x2 0x67700000 0x0 0x20000>,
		      <0x2 0x6a700000 0x0 0x20000>,
		      <0x2 0x68a00000 0x0 0x20000>,
		      <0x2 0x6b700000 0x0 0x20000>,
		      <0x2 0x69a00000 0x0 0x20000>,
		      <0x2 0x58900000 0x0 0x20000>,
		      <0x2 0x5a900000 0x0 0x20000>,
		      <0x2 0x5c000000 0x0 0x20000>,
		      <0x2 0x5d000000 0x0 0x20000>,
		      <0x2 0x5e900000 0x0 0x20000>,
		      <0x2 0x5fc00000 0x0 0x20000>,
		      <0x2 0x61000000 0x0 0x20000>,
		      <0x2 0x62000000 0x0 0x20000>,
		      <0x2 0x4f600000 0x0 0x20000>,
		      <0x2 0x50600000 0x0 0x20000>,
		      <0x2 0x52000000 0x0 0x20000>,
		      <0x2 0x53000000 0x0 0x20000>,
		      <0x2 0x54600000 0x0 0x20000>,
		      <0x2 0x55600000 0x0 0x20000>,
		      <0x2 0x56000000 0x0 0x20000>,
		      <0x2 0x57000000 0x0 0x20000>,
		      <0x2 0x4f032000 0x0 0x1000>,
		      <0x2 0x4f332000 0x0 0x1000>,
		      <0x2 0x50032000 0x0 0x1000>,
		      <0x2 0x50332000 0x0 0x1000>,
		      <0x2 0x54032000 0x0 0x1000>,
		      <0x2 0x55032000 0x0 0x1000>,
		      <0x2 0x54332000 0x0 0x1000>,
		      <0x2 0x55332000 0x0 0x1000>,
		      <0x2 0x58032000 0x0 0x1000>,
		      <0x2 0x58332000 0x0 0x1000>,
		      <0x2 0x58632000 0x0 0x1000>,
		      <0x2 0x5a032000 0x0 0x1000>,
		      <0x2 0x5a332000 0x0 0x1000>,
		      <0x2 0x5a632000 0x0 0x1000>,
		      <0x2 0x5e032000 0x0 0x1000>,
		      <0x2 0x5f632000 0x0 0x1000>,
		      <0x2 0x5f032000 0x0 0x1000>,
		      <0x2 0x5f332000 0x0 0x1000>,
		      <0x2 0x5e332000 0x0 0x1000>,
		      <0x2 0x5e632000 0x0 0x1000>,
		      <0x2 0x5f932000 0x0 0x1000>,
		      <0x2 0x64032000 0x0 0x1000>,
		      <0x2 0x66032000 0x0 0x1000>,
		      <0x2 0x65032000 0x0 0x1000>,
		      <0x2 0x67032000 0x0 0x1000>,
		      <0x2 0x6a032000 0x0 0x1000>,
		      <0x2 0x68032000 0x0 0x1000>,
		      <0x2 0x6b032000 0x0 0x1000>,
		      <0x2 0x69032000 0x0 0x1000>,
		      <0x2 0x6ab32000 0x0 0x1000>,
		      <0x2 0x6bb32000 0x0 0x1000>,
		      <0x2 0x54400000 0x0 0x4000>,
		      <0x2 0x55400000 0x0 0x4000>,
		      <0x2 0x5e700000 0x0 0x4000>,
		      <0x2 0x5fa00000 0x0 0x4000>,
		      <0x2 0x6ac00000 0x0 0x4000>,
		      <0x2 0x6ac80000 0x0 0x4000>,
		      <0x2 0x6bc00000 0x0 0x4000>,
		      <0x2 0x6bc80000 0x0 0x4000>;
		interrupt-parent = <&aic>;
		interrupts = <AIC_IRQ 0 550 IRQ_TYPE_LEVEL_HIGH>,
			     <AIC_IRQ 0 549 IRQ_TYPE_LEVEL_HIGH>,
			     <AIC_IRQ 0 552 IRQ_TYPE_LEVEL_HIGH>,
			     <AIC_IRQ 0 553 IRQ_TYPE_LEVEL_HIGH>,
			     <AIC_IRQ 0 554 IRQ_TYPE_LEVEL_HIGH>,
			     <AIC_IRQ 0 555 IRQ_TYPE_LEVEL_HIGH>,
			     <AIC_IRQ 0 556 IRQ_TYPE_LEVEL_HIGH>,
			     <AIC_IRQ 0 557 IRQ_TYPE_LEVEL_HIGH>,
			     <AIC_IRQ 0 448 IRQ_TYPE_LEVEL_HIGH>,
			     <AIC_IRQ 0 458 IRQ_TYPE_LEVEL_HIGH>,
			     <AIC_IRQ 0 468 IRQ_TYPE_LEVEL_HIGH>,
			     <AIC_IRQ 0 478 IRQ_TYPE_LEVEL_HIGH>,
			     <AIC_IRQ 0 488 IRQ_TYPE_LEVEL_HIGH>,
			     <AIC_IRQ 0 498 IRQ_TYPE_LEVEL_HIGH>,
			     <AIC_IRQ 0 508 IRQ_TYPE_LEVEL_HIGH>,
			     <AIC_IRQ 0 518 IRQ_TYPE_LEVEL_HIGH>,
			     <AIC_IRQ 0 285 IRQ_TYPE_LEVEL_HIGH>,
			     <AIC_IRQ 0 287 IRQ_TYPE_LEVEL_HIGH>,
			     <AIC_IRQ 0 289 IRQ_TYPE_LEVEL_HIGH>,
			     <AIC_IRQ 0 291 IRQ_TYPE_LEVEL_HIGH>,
			     <AIC_IRQ 0 293 IRQ_TYPE_LEVEL_HIGH>,
			     <AIC_IRQ 0 295 IRQ_TYPE_LEVEL_HIGH>,
			     <AIC_IRQ 0 452 IRQ_TYPE_LEVEL_HIGH>,
			     <AIC_IRQ 0 453 IRQ_TYPE_LEVEL_HIGH>,
			     <AIC_IRQ 0 454 IRQ_TYPE_LEVEL_HIGH>,
			     <AIC_IRQ 0 455 IRQ_TYPE_LEVEL_HIGH>,
			     <AIC_IRQ 0 462 IRQ_TYPE_LEVEL_HIGH>,
			     <AIC_IRQ 0 463 IRQ_TYPE_LEVEL_HIGH>,
			     <AIC_IRQ 0 464 IRQ_TYPE_LEVEL_HIGH>,
			     <AIC_IRQ 0 465 IRQ_TYPE_LEVEL_HIGH>,
			     <AIC_IRQ 0 472 IRQ_TYPE_LEVEL_HIGH>,
			     <AIC_IRQ 0 473 IRQ_TYPE_LEVEL_HIGH>,
			     <AIC_IRQ 0 474 IRQ_TYPE_LEVEL_HIGH>,
			     <AIC_IRQ 0 475 IRQ_TYPE_LEVEL_HIGH>,
			     <AIC_IRQ 0 482 IRQ_TYPE_LEVEL_HIGH>,
			     <AIC_IRQ 0 483 IRQ_TYPE_LEVEL_HIGH>,
			     <AIC_IRQ 0 484 IRQ_TYPE_LEVEL_HIGH>,
			     <AIC_IRQ 0 485 IRQ_TYPE_LEVEL_HIGH>,
			     <AIC_IRQ 0 492 IRQ_TYPE_LEVEL_HIGH>,
			     <AIC_IRQ 0 493 IRQ_TYPE_LEVEL_HIGH>,
			     <AIC_IRQ 0 494 IRQ_TYPE_LEVEL_HIGH>,
			     <AIC_IRQ 0 495 IRQ_TYPE_LEVEL_HIGH>,
			     <AIC_IRQ 0 502 IRQ_TYPE_LEVEL_HIGH>,
			     <AIC_IRQ 0 503 IRQ_TYPE_LEVEL_HIGH>,
			     <AIC_IRQ 0 504 IRQ_TYPE_LEVEL_HIGH>,
			     <AIC_IRQ 0 505 IRQ_TYPE_LEVEL_HIGH>,
			     <AIC_IRQ 0 512 IRQ_TYPE_LEVEL_HIGH>,
			     <AIC_IRQ 0 513 IRQ_TYPE_LEVEL_HIGH>,
			     <AIC_IRQ 0 514 IRQ_TYPE_LEVEL_HIGH>,
			     <AIC_IRQ 0 515 IRQ_TYPE_LEVEL_HIGH>,
			     <AIC_IRQ 0 522 IRQ_TYPE_LEVEL_HIGH>,
			     <AIC_IRQ 0 523 IRQ_TYPE_LEVEL_HIGH>,
			     <AIC_IRQ 0 524 IRQ_TYPE_LEVEL_HIGH>,
			     <AIC_IRQ 0 525 IRQ_TYPE_LEVEL_HIGH>,
			     <AIC_IRQ 0 260 IRQ_TYPE_LEVEL_HIGH>,
			     <AIC_IRQ 0 261 IRQ_TYPE_LEVEL_HIGH>,
			     <AIC_IRQ 0 262 IRQ_TYPE_LEVEL_HIGH>,
			     <AIC_IRQ 0 263 IRQ_TYPE_LEVEL_HIGH>,
			     <AIC_IRQ 0 264 IRQ_TYPE_LEVEL_HIGH>,
			     <AIC_IRQ 0 265 IRQ_TYPE_LEVEL_HIGH>,
			     <AIC_IRQ 0 266 IRQ_TYPE_LEVEL_HIGH>,
			     <AIC_IRQ 0 267 IRQ_TYPE_LEVEL_HIGH>,
			     <AIC_IRQ 0 268 IRQ_TYPE_LEVEL_HIGH>,
			     <AIC_IRQ 0 247 IRQ_TYPE_LEVEL_HIGH>,
			     <AIC_IRQ 0 248 IRQ_TYPE_LEVEL_HIGH>,
			     <AIC_IRQ 0 249 IRQ_TYPE_LEVEL_HIGH>,
			     <AIC_IRQ 0 250 IRQ_TYPE_LEVEL_HIGH>,
			     <AIC_IRQ 0 251 IRQ_TYPE_LEVEL_HIGH>,
			     <AIC_IRQ 0 196 IRQ_TYPE_LEVEL_HIGH>,
			     <AIC_IRQ 0 197 IRQ_TYPE_LEVEL_HIGH>,
			     <AIC_IRQ 0 223 IRQ_TYPE_LEVEL_HIGH>,
			     <AIC_IRQ 0 224 IRQ_TYPE_LEVEL_HIGH>,
			     <AIC_IRQ 0 225 IRQ_TYPE_LEVEL_HIGH>,
			     <AIC_IRQ 0 226 IRQ_TYPE_LEVEL_HIGH>,
			     <AIC_IRQ 0 227 IRQ_TYPE_LEVEL_HIGH>,
			     <AIC_IRQ 0 228 IRQ_TYPE_LEVEL_HIGH>,
			     <AIC_IRQ 0 229 IRQ_TYPE_LEVEL_HIGH>,
			     <AIC_IRQ 0 230 IRQ_TYPE_LEVEL_HIGH>,
			     <AIC_IRQ 0 231 IRQ_TYPE_LEVEL_HIGH>,
			     <AIC_IRQ 0 232 IRQ_TYPE_LEVEL_HIGH>,
			     <AIC_IRQ 0 233 IRQ_TYPE_LEVEL_HIGH>,
			     <AIC_IRQ 0 234 IRQ_TYPE_LEVEL_HIGH>,
			     <AIC_IRQ 0 235 IRQ_TYPE_LEVEL_HIGH>,
			     <AIC_IRQ 0 236 IRQ_TYPE_LEVEL_HIGH>,
			     <AIC_IRQ 0 237 IRQ_TYPE_LEVEL_HIGH>,
			     <AIC_IRQ 0 238 IRQ_TYPE_LEVEL_HIGH>,
			     <AIC_IRQ 0 252 IRQ_TYPE_LEVEL_HIGH>,
			     <AIC_IRQ 0 253 IRQ_TYPE_LEVEL_HIGH>,
			     <AIC_IRQ 0 254 IRQ_TYPE_LEVEL_HIGH>,
			     <AIC_IRQ 0 255 IRQ_TYPE_LEVEL_HIGH>,
			     <AIC_IRQ 0 256 IRQ_TYPE_LEVEL_HIGH>,
			     <AIC_IRQ 0 257 IRQ_TYPE_LEVEL_HIGH>,
			     <AIC_IRQ 0 258 IRQ_TYPE_LEVEL_HIGH>,
			     <AIC_IRQ 0 259 IRQ_TYPE_LEVEL_HIGH>,
			     <AIC_IRQ 0 239 IRQ_TYPE_LEVEL_HIGH>,
			     <AIC_IRQ 0 240 IRQ_TYPE_LEVEL_HIGH>,
			     <AIC_IRQ 0 241 IRQ_TYPE_LEVEL_HIGH>,
			     <AIC_IRQ 0 242 IRQ_TYPE_LEVEL_HIGH>,
			     <AIC_IRQ 0 243 IRQ_TYPE_LEVEL_HIGH>,
			     <AIC_IRQ 0 244 IRQ_TYPE_LEVEL_HIGH>,
			     <AIC_IRQ 0 245 IRQ_TYPE_LEVEL_HIGH>,
			     <AIC_IRQ 0 246 IRQ_TYPE_LEVEL_HIGH>,
			     <AIC_IRQ 0 202 IRQ_TYPE_LEVEL_HIGH>,
			     <AIC_IRQ 0 203 IRQ_TYPE_LEVEL_HIGH>,
			     <AIC_IRQ 0 204 IRQ_TYPE_LEVEL_HIGH>,
			     <AIC_IRQ 0 205 IRQ_TYPE_LEVEL_HIGH>,
			     <AIC_IRQ 0 201 IRQ_TYPE_LEVEL_HIGH>,
			     <AIC_IRQ 0 206 IRQ_TYPE_LEVEL_HIGH>,
			     <AIC_IRQ 0 207 IRQ_TYPE_LEVEL_HIGH>,
			     <AIC_IRQ 0 208 IRQ_TYPE_LEVEL_HIGH>,
			     <AIC_IRQ 0 210 IRQ_TYPE_LEVEL_HIGH>,
			     <AIC_IRQ 0 211 IRQ_TYPE_LEVEL_HIGH>,
			     <AIC_IRQ 0 212 IRQ_TYPE_LEVEL_HIGH>,
			     <AIC_IRQ 0 213 IRQ_TYPE_LEVEL_HIGH>,
			     <AIC_IRQ 0 214 IRQ_TYPE_LEVEL_HIGH>,
			     <AIC_IRQ 0 215 IRQ_TYPE_LEVEL_HIGH>,
			     <AIC_IRQ 0 209 IRQ_TYPE_LEVEL_HIGH>,
			     <AIC_IRQ 0 219 IRQ_TYPE_LEVEL_HIGH>,
			     <AIC_IRQ 0 216 IRQ_TYPE_LEVEL_HIGH>,
			     <AIC_IRQ 0 217 IRQ_TYPE_LEVEL_HIGH>,
			     <AIC_IRQ 0 218 IRQ_TYPE_LEVEL_HIGH>,
			     <AIC_IRQ 0 220 IRQ_TYPE_LEVEL_HIGH>,
			     <AIC_IRQ 0 221 IRQ_TYPE_LEVEL_HIGH>,
			     <AIC_IRQ 0 189 IRQ_TYPE_LEVEL_HIGH>,
			     <AIC_IRQ 0 190 IRQ_TYPE_LEVEL_HIGH>,
			     <AIC_IRQ 0 191 IRQ_TYPE_LEVEL_HIGH>,
			     <AIC_IRQ 0 192 IRQ_TYPE_LEVEL_HIGH>,
			     <AIC_IRQ 0 193 IRQ_TYPE_LEVEL_HIGH>,
			     <AIC_IRQ 0 194 IRQ_TYPE_LEVEL_HIGH>,
			     <AIC_IRQ 0 195 IRQ_TYPE_LEVEL_HIGH>,
			     <AIC_IRQ 0 198 IRQ_TYPE_LEVEL_HIGH>,
			     <AIC_IRQ 0 199 IRQ_TYPE_LEVEL_HIGH>,
			     <AIC_IRQ 0 200 IRQ_TYPE_LEVEL_HIGH>,
			     <AIC_IRQ 0 1576 IRQ_TYPE_LEVEL_HIGH>,
			     <AIC_IRQ 0 1578 IRQ_TYPE_LEVEL_HIGH>,
			     <AIC_IRQ 0 1577 IRQ_TYPE_LEVEL_HIGH>,
			     <AIC_IRQ 0 1579 IRQ_TYPE_LEVEL_HIGH>,
			     <AIC_IRQ 0 1580 IRQ_TYPE_LEVEL_HIGH>;
		status = "disabled";
	};

	soc_events: event-log@28e080000 {
		compatible = "apple,t6002-event-log", "apple,soc-event-log";
		reg = <0x2 0x8e080000 0x0 0x80000>,
		      <0x2 0x8e580000 0x0 0x80000>,
		      <0x2 0x8e680000 0x0 0x74000>,
		      <0x2 0x8e45c000 0x0 0x4000>,
		      <0x2 0x8e460000 0x0 0x4000>,
		      <0x2 0x8e464000 0x0 0x4000>,
		      <0x2 0x8e468000 0x0 0x4000>,
		      <0x2 0x8e46c000 0x0 0x4000>,
		      <0x2 0x8e458000 0x0 0x4000>,
		      <0x2 0x8e428000 0x0 0x8000>,
		      <0x2 0x8e430000 0x0 0x8000>,
		      <0x2 0x8e418000 0x0 0x8000>,
		      <0x2 0x8e410000 0x0 0x8000>,
		      <0x2 0x8e420000 0x0 0x8000>,
		      <0x2 0x8e400000 0x0 0x8000>,
		      <0x2 0x8e408000 0x0 0x8000>,
		      <0x2 0x8e438000 0x0 0x8000>,
		      <0x2 0x8e440000 0x0 0x8000>,
		      <0x2 0x92200000 0x0 0x80000>,
		      <0x2 0x8e000000 0x0 0x80000>,
		      <0x2 0x8e600000 0x0 0x4c000>,
		      <0x2 0x92280000 0x0 0x74000>,
		      <0x2 0x85838000 0x0 0x8000>,
		      <0x5 0x09838000 0x0 0x8000>,
		      <0x2 0x85868000 0x0 0x4000>,
		      <0x5 0x09868000 0x0 0x4000>,
		      <0x4 0x04e20000 0x0 0x4000>,
		      <0x4 0x04e20000 0x0 0x4000>;
		interrupt-parent = <&aic>;
		interrupts = <AIC_IRQ 0 444 IRQ_TYPE_LEVEL_HIGH>,
			     <AIC_IRQ 0 445 IRQ_TYPE_LEVEL_HIGH>,
			     <AIC_IRQ 0 446 IRQ_TYPE_LEVEL_HIGH>,
			     <AIC_IRQ 0 70 IRQ_TYPE_LEVEL_HIGH>,
			     <AIC_IRQ 0 71 IRQ_TYPE_LEVEL_HIGH>,
			     <AIC_IRQ 0 72 IRQ_TYPE_LEVEL_HIGH>,
			     <AIC_IRQ 0 73 IRQ_TYPE_LEVEL_HIGH>,
			     <AIC_IRQ 0 74 IRQ_TYPE_LEVEL_HIGH>,
			     <AIC_IRQ 0 75 IRQ_TYPE_LEVEL_HIGH>,
			     <AIC_IRQ 0 76 IRQ_TYPE_LEVEL_HIGH>,
			     <AIC_IRQ 0 77 IRQ_TYPE_LEVEL_HIGH>,
			     <AIC_IRQ 0 78 IRQ_TYPE_LEVEL_HIGH>,
			     <AIC_IRQ 0 79 IRQ_TYPE_LEVEL_HIGH>,
			     <AIC_IRQ 0 80 IRQ_TYPE_LEVEL_HIGH>,
			     <AIC_IRQ 0 81 IRQ_TYPE_LEVEL_HIGH>,
			     <AIC_IRQ 0 82 IRQ_TYPE_LEVEL_HIGH>,
			     <AIC_IRQ 0 83 IRQ_TYPE_LEVEL_HIGH>,
			     <AIC_IRQ 0 84 IRQ_TYPE_LEVEL_HIGH>,
			     <AIC_IRQ 0 424 IRQ_TYPE_LEVEL_HIGH>,
			     <AIC_IRQ 0 425 IRQ_TYPE_LEVEL_HIGH>,
			     <AIC_IRQ 0 426 IRQ_TYPE_LEVEL_HIGH>,
			     <AIC_IRQ 0 442 IRQ_TYPE_LEVEL_HIGH>,
			     <AIC_IRQ 0 763 IRQ_TYPE_LEVEL_HIGH>,
			     <AIC_IRQ 0 790 IRQ_TYPE_LEVEL_HIGH>,
			     <AIC_IRQ 0 418 IRQ_TYPE_LEVEL_HIGH>,
			     <AIC_IRQ 0 421 IRQ_TYPE_LEVEL_HIGH>,
			     <AIC_IRQ 0 1067 IRQ_TYPE_LEVEL_HIGH>,
			     <AIC_IRQ 0 1068 IRQ_TYPE_LEVEL_HIGH>;
		status = "disabled";
	};

	pwm1: timer-pwm@39b030000 {
		compatible = "apple,t6000-pwm", "apple,pwm";
		reg = <0x3 0x9b030000 0x0 0x4000>;
		interrupt-parent = <&aic>;
		interrupts = <AIC_IRQ 0 1128 IRQ_TYPE_LEVEL_HIGH>;
		power-domains = <&ps_fpwm1>;
		status = "disabled";
	};
};

&die1 {
	mcc_die1: memory-controller@200000000 {
		compatible = "apple,t6000-mcc", "apple,mcc";
		reg = <0x2 0x00000000 0x0 0x1000000>,
		      <0x2 0x01000000 0x0 0x1000000>,
		      <0x2 0x02000000 0x0 0x1000000>,
		      <0x2 0x03000000 0x0 0x1000000>,
		      <0x2 0x04000000 0x0 0x1000000>,
		      <0x2 0x05000000 0x0 0x1000000>,
		      <0x2 0x06000000 0x0 0x1000000>,
		      <0x2 0x07000000 0x0 0x1000000>;
		status = "disabled";
	};

	soc_errors_die1: error-handler@200000000 {
		compatible = "apple,t6002-error-handler", "apple,soc-error-handler";
		reg = <0x2 0x00000000 0x0 0x1000000>,
		      <0x2 0x01000000 0x0 0x1000000>,
		      <0x2 0x02000000 0x0 0x1000000>,
		      <0x2 0x03000000 0x0 0x1000000>,
		      <0x2 0x04000000 0x0 0x1000000>,
		      <0x2 0x05000000 0x0 0x1000000>,
		      <0x2 0x06000000 0x0 0x1000000>,
		      <0x2 0x07000000 0x0 0x1000000>,
		      <0x2 0x82000000 0x0 0x4000>,
		      <0x3 0x04000000 0x0 0x4000>,
		      <0x3 0x83000000 0x0 0x4000>,
		      <0x4 0x02000000 0x0 0x4000>,
		      <0x4 0x82000000 0x0 0x4000>,
		      <0x5 0x02000000 0x0 0x4000>,
		      <0x2 0x58d00000 0x0 0x20000>,
		      <0x2 0x59100000 0x0 0x20000>,
		      <0x2 0x5ad00000 0x0 0x20000>,
		      <0x2 0x5b100000 0x0 0x20000>,
		      <0x2 0x60000000 0x0 0x20000>,
		      <0x2 0x60400000 0x0 0x20000>,
		      <0x2 0x59500000 0x0 0x20000>,
		      <0x2 0x5b500000 0x0 0x20000>,
		      <0x2 0x5b900000 0x0 0x20000>,
		      <0x2 0x4fa00000 0x0 0x20000>,
		      <0x2 0x50a00000 0x0 0x20000>,
		      <0x2 0x50e00000 0x0 0x20000>,
		      <0x2 0x4fa80000 0x0 0x20000>,
		      <0x2 0x50a80000 0x0 0x20000>,
		      <0x2 0x64300000 0x0 0x20000>,
		      <0x2 0x65300000 0x0 0x20000>,
		      <0x2 0x64700000 0x0 0x20000>,
		      <0x2 0x66300000 0x0 0x20000>,
		      <0x2 0x65700000 0x0 0x20000>,
		      <0x2 0x67300000 0x0 0x20000>,
		      <0x2 0x6a300000 0x0 0x20000>,
		      <0x2 0x68600000 0x0 0x20000>,
		      <0x2 0x6b300000 0x0 0x20000>,
		      <0x2 0x69600000 0x0 0x20000>,
		      <0x2 0x64b00000 0x0 0x20000>,
		      <0x2 0x66700000 0x0 0x20000>,
		      <0x2 0x65b00000 0x0 0x20000>,
		      <0x2 0x67700000 0x0 0x20000>,
		      <0x2 0x6a700000 0x0 0x20000>,
		      <0x2 0x68a00000 0x0 0x20000>,
		      <0x2 0x6b700000 0x0 0x20000>,
		      <0x2 0x69a00000 0x0 0x20000>,
		      <0x2 0x58900000 0x0 0x20000>,
		      <0x2 0x5a900000 0x0 0x20000>,
		      <0x2 0x5c000000 0x0 0x20000>,
		      <0x2 0x5d000000 0x0 0x20000>,
		      <0x2 0x5e900000 0x0 0x20000>,
		      <0x2 0x5fc00000 0x0 0x20000>,
		      <0x2 0x61000000 0x0 0x20000>,
		      <0x2 0x62000000 0x0 0x20000>,
		      <0x2 0x4f600000 0x0 0x20000>,
		      <0x2 0x50600000 0x0 0x20000>,
		      <0x2 0x52000000 0x0 0x20000>,
		      <0x2 0x53000000 0x0 0x20000>,
		      <0x2 0x54600000 0x0 0x20000>,
		      <0x2 0x55600000 0x0 0x20000>,
		      <0x2 0x56000000 0x0 0x20000>,
		      <0x2 0x57000000 0x0 0x20000>,
		      <0x2 0x4f032000 0x0 0x1000>,
		      <0x2 0x4f332000 0x0 0x1000>,
		      <0x2 0x50032000 0x0 0x1000>,
		      <0x2 0x50332000 0x0 0x1000>,
		      <0x2 0x54032000 0x0 0x1000>,
		      <0x2 0x55032000 0x0 0x1000>,
		      <0x2 0x54332000 0x0 0x1000>,
		      <0x2 0x55332000 0x0 0x1000>,
		      <0x2 0x58032000 0x0 0x1000>,
		      <0x2 0x58332000 0x0 0x1000>,
		      <0x2 0x58632000 0x0 0x1000>,
		      <0x2 0x5a032000 0x0 0x1000>,
		      <0x2 0x5a332000 0x0 0x1000>,
		      <0x2 0x5a632000 0x0 0x1000>,
		      <0x2 0x5e032000 0x0 0x1000>,
		      <0x2 0x5f632000 0x0 0x1000>,
		      <0x2 0x5f032000 0x0 0x1000>,
		      <0x2 0x5f332000 0x0 0x1000>,
		      <0x2 0x5e332000 0x0 0x1000>,
		      <0x2 0x5e632000 0x0 0x1000>,
		      <0x2 0x5f932000 0x0 0x1000>,
		      <0x2 0x64032000 0x0 0x1000>,
		      <0x2 0x66032000 0x0 0x1000>,
		      <0x2 0x65032000 0x0 0x1000>,
		      <0x2 0x67032000 0x0 0x1000>,
		      <0x2 0x6a032000 0x0 0x1000>,
		      <0x2 0x68032000 0x0 0x1000>,
		      <0x2 0x6b032000 0x0 0x1000>,
		      <0x2 0x69032000 0x0 0x1000>,
		      <0x2 0x6ab32000 0x0 0x1000>,
		      <0x2 0x6bb32000 0x0 0x1000>,
		      <0x2 0x54400000 0x0 0x4000>,
		      <0x2 0x55400000 0x0 0x4000>,
		      <0x2 0x5e700000 0x0 0x4000>,
		      <0x2 0x5fa00000 0x0 0x4000>,
		      <0x2 0x6ac00000 0x0 0x4000>,
		      <0x2 0x6ac80000 0x0 0x4000>,
		      <0x2 0x6bc00000 0x0 0x4000>,
		      <0x2 0x6bc80000 0x0 0x4000>;
		interrupt-parent = <&aic>;
		interrupts = <AIC_IRQ 1 518 IRQ_TYPE_LEVEL_HIGH>,
			     <AIC_IRQ 1 508 IRQ_TYPE_LEVEL_HIGH>,
			     <AIC_IRQ 1 498 IRQ_TYPE_LEVEL_HIGH>,
			     <AIC_IRQ 1 488 IRQ_TYPE_LEVEL_HIGH>,
			     <AIC_IRQ 1 478 IRQ_TYPE_LEVEL_HIGH>,
			     <AIC_IRQ 1 468 IRQ_TYPE_LEVEL_HIGH>,
			     <AIC_IRQ 1 458 IRQ_TYPE_LEVEL_HIGH>,
			     <AIC_IRQ 1 448 IRQ_TYPE_LEVEL_HIGH>,
			     <AIC_IRQ 1 285 IRQ_TYPE_LEVEL_HIGH>,
			     <AIC_IRQ 1 287 IRQ_TYPE_LEVEL_HIGH>,
			     <AIC_IRQ 1 289 IRQ_TYPE_LEVEL_HIGH>,
			     <AIC_IRQ 1 291 IRQ_TYPE_LEVEL_HIGH>,
			     <AIC_IRQ 1 293 IRQ_TYPE_LEVEL_HIGH>,
			     <AIC_IRQ 1 295 IRQ_TYPE_LEVEL_HIGH>,
			     <AIC_IRQ 1 452 IRQ_TYPE_LEVEL_HIGH>,
			     <AIC_IRQ 1 453 IRQ_TYPE_LEVEL_HIGH>,
			     <AIC_IRQ 1 454 IRQ_TYPE_LEVEL_HIGH>,
			     <AIC_IRQ 1 455 IRQ_TYPE_LEVEL_HIGH>,
			     <AIC_IRQ 1 462 IRQ_TYPE_LEVEL_HIGH>,
			     <AIC_IRQ 1 463 IRQ_TYPE_LEVEL_HIGH>,
			     <AIC_IRQ 1 464 IRQ_TYPE_LEVEL_HIGH>,
			     <AIC_IRQ 1 465 IRQ_TYPE_LEVEL_HIGH>,
			     <AIC_IRQ 1 472 IRQ_TYPE_LEVEL_HIGH>,
			     <AIC_IRQ 1 473 IRQ_TYPE_LEVEL_HIGH>,
			     <AIC_IRQ 1 474 IRQ_TYPE_LEVEL_HIGH>,
			     <AIC_IRQ 1 475 IRQ_TYPE_LEVEL_HIGH>,
			     <AIC_IRQ 1 482 IRQ_TYPE_LEVEL_HIGH>,
			     <AIC_IRQ 1 483 IRQ_TYPE_LEVEL_HIGH>,
			     <AIC_IRQ 1 484 IRQ_TYPE_LEVEL_HIGH>,
			     <AIC_IRQ 1 485 IRQ_TYPE_LEVEL_HIGH>,
			     <AIC_IRQ 1 492 IRQ_TYPE_LEVEL_HIGH>,
			     <AIC_IRQ 1 493 IRQ_TYPE_LEVEL_HIGH>,
			     <AIC_IRQ 1 494 IRQ_TYPE_LEVEL_HIGH>,
			     <AIC_IRQ 1 495 IRQ_TYPE_LEVEL_HIGH>,
			     <AIC_IRQ 1 502 IRQ_TYPE_LEVEL_HIGH>,
			     <AIC_IRQ 1 503 IRQ_TYPE_LEVEL_HIGH>,
			     <AIC_IRQ 1 504 IRQ_TYPE_LEVEL_HIGH>,
			     <AIC_IRQ 1 505 IRQ_TYPE_LEVEL_HIGH>,
			     <AIC_IRQ 1 512 IRQ_TYPE_LEVEL_HIGH>,
			     <AIC_IRQ 1 513 IRQ_TYPE_LEVEL_HIGH>,
			     <AIC_IRQ 1 514 IRQ_TYPE_LEVEL_HIGH>,
			     <AIC_IRQ 1 515 IRQ_TYPE_LEVEL_HIGH>,
			     <AIC_IRQ 1 522 IRQ_TYPE_LEVEL_HIGH>,
			     <AIC_IRQ 1 523 IRQ_TYPE_LEVEL_HIGH>,
			     <AIC_IRQ 1 524 IRQ_TYPE_LEVEL_HIGH>,
			     <AIC_IRQ 1 525 IRQ_TYPE_LEVEL_HIGH>,
			     <AIC_IRQ 1 260 IRQ_TYPE_LEVEL_HIGH>,
			     <AIC_IRQ 1 261 IRQ_TYPE_LEVEL_HIGH>,
			     <AIC_IRQ 1 262 IRQ_TYPE_LEVEL_HIGH>,
			     <AIC_IRQ 1 263 IRQ_TYPE_LEVEL_HIGH>,
			     <AIC_IRQ 1 264 IRQ_TYPE_LEVEL_HIGH>,
			     <AIC_IRQ 1 265 IRQ_TYPE_LEVEL_HIGH>,
			     <AIC_IRQ 1 266 IRQ_TYPE_LEVEL_HIGH>,
			     <AIC_IRQ 1 267 IRQ_TYPE_LEVEL_HIGH>,
			     <AIC_IRQ 1 268 IRQ_TYPE_LEVEL_HIGH>,
			     <AIC_IRQ 1 247 IRQ_TYPE_LEVEL_HIGH>,
			     <AIC_IRQ 1 248 IRQ_TYPE_LEVEL_HIGH>,
			     <AIC_IRQ 1 249 IRQ_TYPE_LEVEL_HIGH>,
			     <AIC_IRQ 1 250 IRQ_TYPE_LEVEL_HIGH>,
			     <AIC_IRQ 1 251 IRQ_TYPE_LEVEL_HIGH>,
			     <AIC_IRQ 1 196 IRQ_TYPE_LEVEL_HIGH>,
			     <AIC_IRQ 1 197 IRQ_TYPE_LEVEL_HIGH>,
			     <AIC_IRQ 1 223 IRQ_TYPE_LEVEL_HIGH>,
			     <AIC_IRQ 1 224 IRQ_TYPE_LEVEL_HIGH>,
			     <AIC_IRQ 1 225 IRQ_TYPE_LEVEL_HIGH>,
			     <AIC_IRQ 1 226 IRQ_TYPE_LEVEL_HIGH>,
			     <AIC_IRQ 1 227 IRQ_TYPE_LEVEL_HIGH>,
			     <AIC_IRQ 1 228 IRQ_TYPE_LEVEL_HIGH>,
			     <AIC_IRQ 1 229 IRQ_TYPE_LEVEL_HIGH>,
			     <AIC_IRQ 1 230 IRQ_TYPE_LEVEL_HIGH>,
			     <AIC_IRQ 1 231 IRQ_TYPE_LEVEL_HIGH>,
			     <AIC_IRQ 1 232 IRQ_TYPE_LEVEL_HIGH>,
			     <AIC_IRQ 1 233 IRQ_TYPE_LEVEL_HIGH>,
			     <AIC_IRQ 1 234 IRQ_TYPE_LEVEL_HIGH>,
			     <AIC_IRQ 1 235 IRQ_TYPE_LEVEL_HIGH>,
			     <AIC_IRQ 1 236 IRQ_TYPE_LEVEL_HIGH>,
			     <AIC_IRQ 1 237 IRQ_TYPE_LEVEL_HIGH>,
			     <AIC_IRQ 1 238 IRQ_TYPE_LEVEL_HIGH>,
			     <AIC_IRQ 1 252 IRQ_TYPE_LEVEL_HIGH>,
			     <AIC_IRQ 1 253 IRQ_TYPE_LEVEL_HIGH>,
			     <AIC_IRQ 1 254 IRQ_TYPE_LEVEL_HIGH>,
			     <AIC_IRQ 1 255 IRQ_TYPE_LEVEL_HIGH>,
			     <AIC_IRQ 1 256 IRQ_TYPE_LEVEL_HIGH>,
			     <AIC_IRQ 1 257 IRQ_TYPE_LEVEL_HIGH>,
			     <AIC_IRQ 1 258 IRQ_TYPE_LEVEL_HIGH>,
			     <AIC_IRQ 1 259 IRQ_TYPE_LEVEL_HIGH>,
			     <AIC_IRQ 1 239 IRQ_TYPE_LEVEL_HIGH>,
			     <AIC_IRQ 1 240 IRQ_TYPE_LEVEL_HIGH>,
			     <AIC_IRQ 1 241 IRQ_TYPE_LEVEL_HIGH>,
			     <AIC_IRQ 1 242 IRQ_TYPE_LEVEL_HIGH>,
			     <AIC_IRQ 1 243 IRQ_TYPE_LEVEL_HIGH>,
			     <AIC_IRQ 1 244 IRQ_TYPE_LEVEL_HIGH>,
			     <AIC_IRQ 1 245 IRQ_TYPE_LEVEL_HIGH>,
			     <AIC_IRQ 1 246 IRQ_TYPE_LEVEL_HIGH>,
			     <AIC_IRQ 1 202 IRQ_TYPE_LEVEL_HIGH>,
			     <AIC_IRQ 1 203 IRQ_TYPE_LEVEL_HIGH>,
			     <AIC_IRQ 1 204 IRQ_TYPE_LEVEL_HIGH>,
			     <AIC_IRQ 1 205 IRQ_TYPE_LEVEL_HIGH>,
			     <AIC_IRQ 1 201 IRQ_TYPE_LEVEL_HIGH>,
			     <AIC_IRQ 1 206 IRQ_TYPE_LEVEL_HIGH>,
			     <AIC_IRQ 1 207 IRQ_TYPE_LEVEL_HIGH>,
			     <AIC_IRQ 1 208 IRQ_TYPE_LEVEL_HIGH>,
			     <AIC_IRQ 1 210 IRQ_TYPE_LEVEL_HIGH>,
			     <AIC_IRQ 1 211 IRQ_TYPE_LEVEL_HIGH>,
			     <AIC_IRQ 1 212 IRQ_TYPE_LEVEL_HIGH>,
			     <AIC_IRQ 1 213 IRQ_TYPE_LEVEL_HIGH>,
			     <AIC_IRQ 1 214 IRQ_TYPE_LEVEL_HIGH>,
			     <AIC_IRQ 1 215 IRQ_TYPE_LEVEL_HIGH>,
			     <AIC_IRQ 1 209 IRQ_TYPE_LEVEL_HIGH>,
			     <AIC_IRQ 1 219 IRQ_TYPE_LEVEL_HIGH>,
			     <AIC_IRQ 1 216 IRQ_TYPE_LEVEL_HIGH>,
			     <AIC_IRQ 1 217 IRQ_TYPE_LEVEL_HIGH>,
			     <AIC_IRQ 1 218 IRQ_TYPE_LEVEL_HIGH>,
			     <AIC_IRQ 1 220 IRQ_TYPE_LEVEL_HIGH>,
			     <AIC_IRQ 1 221 IRQ_TYPE_LEVEL_HIGH>,
			     <AIC_IRQ 1 189 IRQ_TYPE_LEVEL_HIGH>,
			     <AIC_IRQ 1 190 IRQ_TYPE_LEVEL_HIGH>,
			     <AIC_IRQ 1 191 IRQ_TYPE_LEVEL_HIGH>,
			     <AIC_IRQ 1 192 IRQ_TYPE_LEVEL_HIGH>,
			     <AIC_IRQ 1 193 IRQ_TYPE_LEVEL_HIGH>,
			     <AIC_IRQ 1 194 IRQ_TYPE_LEVEL_HIGH>,
			     <AIC_IRQ 1 195 IRQ_TYPE_LEVEL_HIGH>,
			     <AIC_IRQ 1 198 IRQ_TYPE_LEVEL_HIGH>,
			     <AIC_IRQ 1 199 IRQ_TYPE_LEVEL_HIGH>,
			     <AIC_IRQ 1 200 IRQ_TYPE_LEVEL_HIGH>,
			     <AIC_IRQ 1 1576 IRQ_TYPE_LEVEL_HIGH>,
			     <AIC_IRQ 1 1578 IRQ_TYPE_LEVEL_HIGH>,
			     <AIC_IRQ 1 1577 IRQ_TYPE_LEVEL_HIGH>,
			     <AIC_IRQ 1 1579 IRQ_TYPE_LEVEL_HIGH>,
			     <AIC_IRQ 1 1580 IRQ_TYPE_LEVEL_HIGH>;
		status = "disabled";
	};

	soc_events_die1: event-log@28e080000 {
		compatible = "apple,t6002-event-log", "apple,soc-event-log";
		reg = <0x2 0x8e080000 0x0 0x80000>,
		      <0x2 0x8e580000 0x0 0x80000>,
		      <0x2 0x8e680000 0x0 0x74000>,
		      <0x2 0x8e45c000 0x0 0x4000>,
		      <0x2 0x8e460000 0x0 0x4000>,
		      <0x2 0x8e464000 0x0 0x4000>,
		      <0x2 0x8e468000 0x0 0x4000>,
		      <0x2 0x8e46c000 0x0 0x4000>,
		      <0x2 0x8e458000 0x0 0x4000>,
		      <0x2 0x8e428000 0x0 0x8000>,
		      <0x2 0x8e430000 0x0 0x8000>,
		      <0x2 0x8e418000 0x0 0x8000>,
		      <0x2 0x8e410000 0x0 0x8000>,
		      <0x2 0x8e420000 0x0 0x8000>,
		      <0x2 0x8e400000 0x0 0x8000>,
		      <0x2 0x8e408000 0x0 0x8000>,
		      <0x2 0x8e438000 0x0 0x8000>,
		      <0x2 0x8e440000 0x0 0x8000>,
		      <0x2 0x92200000 0x0 0x80000>,
		      <0x2 0x8e000000 0x0 0x80000>,
		      <0x2 0x8e600000 0x0 0x4c000>,
		      <0x2 0x92280000 0x0 0x74000>,
		      <0x2 0x85838000 0x0 0x8000>,
		      <0x5 0x09838000 0x0 0x8000>,
		      <0x2 0x85868000 0x0 0x4000>,
		      <0x5 0x09868000 0x0 0x4000>;
		interrupt-parent = <&aic>;
		interrupts = <AIC_IRQ 1 444 IRQ_TYPE_LEVEL_HIGH>,
			     <AIC_IRQ 1 445 IRQ_TYPE_LEVEL_HIGH>,
			     <AIC_IRQ 1 446 IRQ_TYPE_LEVEL_HIGH>,
			     <AIC_IRQ 1 70 IRQ_TYPE_LEVEL_HIGH>,
			     <AIC_IRQ 1 71 IRQ_TYPE_LEVEL_HIGH>,
			     <AIC_IRQ 1 72 IRQ_TYPE_LEVEL_HIGH>,
			     <AIC_IRQ 1 73 IRQ_TYPE_LEVEL_HIGH>,
			     <AIC_IRQ 1 74 IRQ_TYPE_LEVEL_HIGH>,
			     <AIC_IRQ 1 75 IRQ_TYPE_LEVEL_HIGH>,
			     <AIC_IRQ 1 76 IRQ_TYPE_LEVEL_HIGH>,
			     <AIC_IRQ 1 77 IRQ_TYPE_LEVEL_HIGH>,
			     <AIC_IRQ 1 78 IRQ_TYPE_LEVEL_HIGH>,
			     <AIC_IRQ 1 79 IRQ_TYPE_LEVEL_HIGH>,
			     <AIC_IRQ 1 80 IRQ_TYPE_LEVEL_HIGH>,
			     <AIC_IRQ 1 81 IRQ_TYPE_LEVEL_HIGH>,
			     <AIC_IRQ 1 82 IRQ_TYPE_LEVEL_HIGH>,
			     <AIC_IRQ 1 83 IRQ_TYPE_LEVEL_HIGH>,
			     <AIC_IRQ 1 84 IRQ_TYPE_LEVEL_HIGH>,
			     <AIC_IRQ 1 424 IRQ_TYPE_LEVEL_HIGH>,
			     <AIC_IRQ 1 425 IRQ_TYPE_LEVEL_HIGH>,
			     <AIC_IRQ 1 426 IRQ_TYPE_LEVEL_HIGH>,
			     <AIC_IRQ 1 442 IRQ_TYPE_LEVEL_HIGH>,
			     <AIC_IRQ 1 763 IRQ_TYPE_LEVEL_HIGH>,
			     <AIC_IRQ 1 790 IRQ_TYPE_LEVEL_HIGH>,
			     <AIC_IRQ 1 418 IRQ_TYPE_LEVEL_HIGH>,
			     <AIC_IRQ 1 421 IRQ_TYPE_LEVEL_HIGH>;
		status = "disabled";
	};
};

&ave {
	reg = <0x4 0x0d100000 0x0 0x45c000>,
	      <0x4 0x0d050000 0x0 0x8000>,
	      <0x4 0x0d800000 0x0 0x800000>,
	      <0x2 0x8e588000 0x0 0x24>,
	      <0x4 0x0c000000 0x0 0x1000000>;
	reg-names = "codec", "mailbox", "coproc", "pmgr", "pio";
	clocks = <&peripheral_clocks 350>;
};
